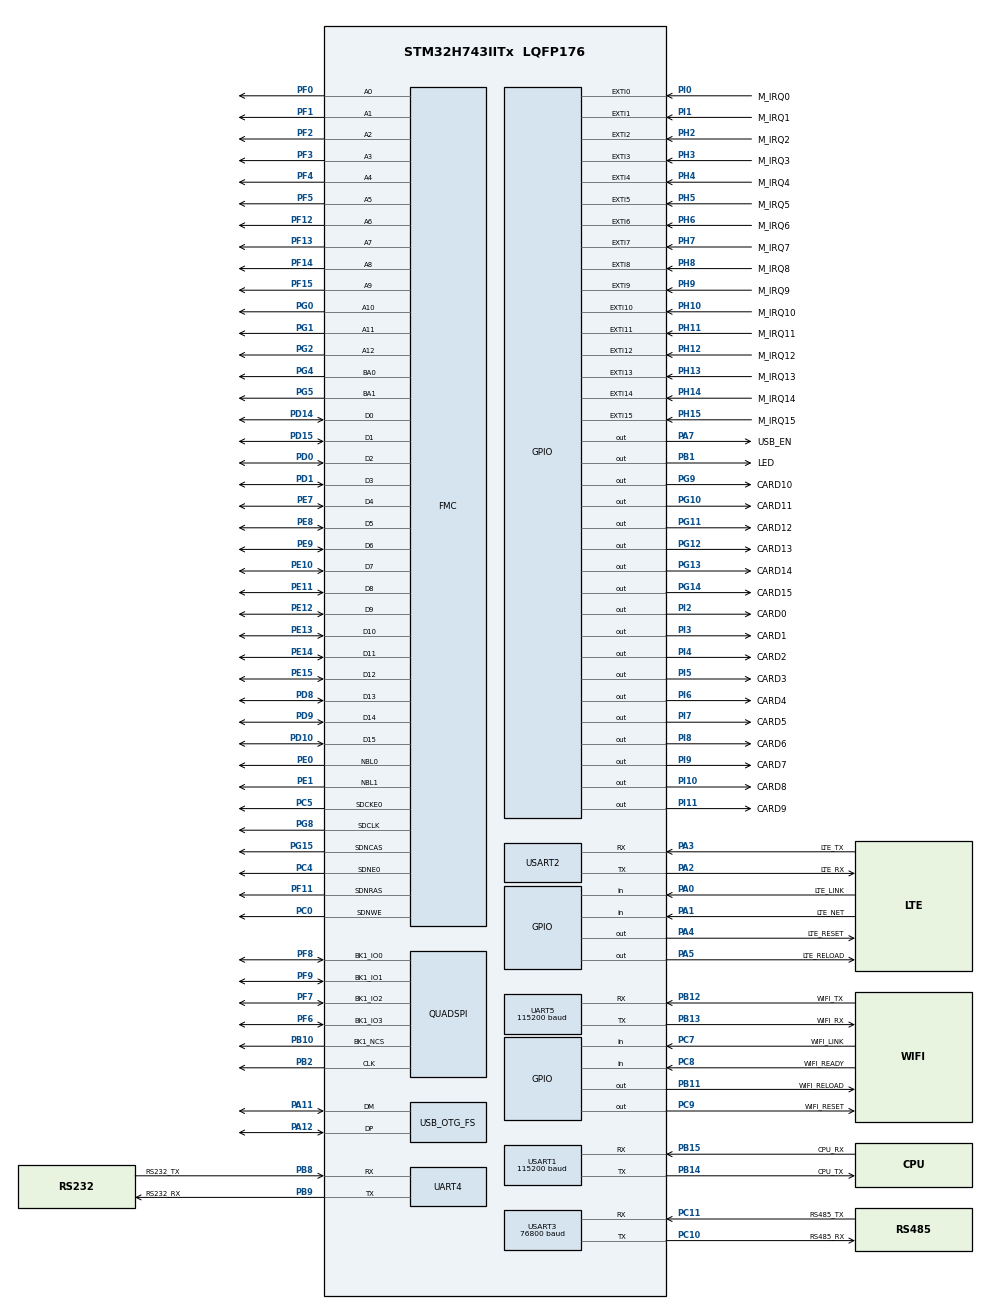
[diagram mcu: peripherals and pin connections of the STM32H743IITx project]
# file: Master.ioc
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CORTEX_M7.CPU_ICache=Enabled
Dma.Request0=USART3_RX
Dma.Request1=USART3_TX
Dma.Request2=UART5_RX
Dma.Request3=UART5_TX
Dma.Request4=USART1_RX
Dma.Request5=USART1_TX
Dma.Request6=USART2_RX
Dma.Request7=UART4_RX
Dma.Request8=UART4_TX
Dma.Request9=USART2_TX
Dma.UART4_RX.7.Direction=DMA_PERIPH_TO_MEMORY
Dma.UART4_RX.7.EventEnable=DISABLE
Dma.UART4_RX.7.FIFOMode=DMA_FIFOMODE_DISABLE
Dma.UART4_RX.7.Instance=DMA1_Stream1
Dma.UART4_RX.7.MemDataAlignment=DMA_MDATAALIGN_BYTE
Dma.UART4_RX.7.MemInc=DMA_MINC_ENABLE
Dma.UART4_RX.7.Mode=DMA_NORMAL
Dma.UART4_RX.7.PeriphDataAlignment=DMA_PDATAALIGN_BYTE
Dma.UART4_RX.7.PeriphInc=DMA_PINC_DISABLE
Dma.UART4_RX.7.Polarity=HAL_DMAMUX_REQ_GEN_RISING
Dma.UART4_RX.7.Priority=DMA_PRIORITY_LOW
Dma.UART4_RX.7.RequestNumber=1
Dma.UART4_RX.7.SignalID=NONE
Dma.UART4_RX.7.SyncEnable=DISABLE
Dma.UART4_RX.7.SyncPolarity=HAL_DMAMUX_SYNC_NO_EVENT
Dma.UART4_RX.7.SyncRequestNumber=1
Dma.UART4_RX.7.SyncSignalID=NONE
Dma.UART4_TX.8.Direction=DMA_MEMORY_TO_PERIPH
Dma.UART4_TX.8.EventEnable=DISABLE
Dma.UART4_TX.8.FIFOMode=DMA_FIFOMODE_DISABLE
Dma.UART4_TX.8.Instance=DMA1_Stream4
Dma.UART4_TX.8.MemDataAlignment=DMA_MDATAALIGN_BYTE
Dma.UART4_TX.8.MemInc=DMA_MINC_ENABLE
Dma.UART4_TX.8.Mode=DMA_NORMAL
Dma.UART4_TX.8.PeriphDataAlignment=DMA_PDATAALIGN_BYTE
Dma.UART4_TX.8.PeriphInc=DMA_PINC_DISABLE
Dma.UART4_TX.8.Polarity=HAL_DMAMUX_REQ_GEN_RISING
Dma.UART4_TX.8.Priority=DMA_PRIORITY_LOW
Dma.UART4_TX.8.RequestNumber=1
Dma.UART4_TX.8.SignalID=NONE
Dma.UART4_TX.8.SyncEnable=DISABLE
Dma.UART4_TX.8.SyncPolarity=HAL_DMAMUX_SYNC_NO_EVENT
Dma.UART4_TX.8.SyncRequestNumber=1
Dma.UART4_TX.8.SyncSignalID=NONE
Dma.UART5_RX.2.Direction=DMA_PERIPH_TO_MEMORY
Dma.UART5_RX.2.EventEnable=DISABLE
Dma.UART5_RX.2.FIFOMode=DMA_FIFOMODE_DISABLE
Dma.UART5_RX.2.Instance=DMA1_Stream6
Dma.UART5_RX.2.MemDataAlignment=DMA_MDATAALIGN_BYTE
Dma.UART5_RX.2.MemInc=DMA_MINC_ENABLE
Dma.UART5_RX.2.Mode=DMA_NORMAL
Dma.UART5_RX.2.PeriphDataAlignment=DMA_PDATAALIGN_BYTE
Dma.UART5_RX.2.PeriphInc=DMA_PINC_DISABLE
Dma.UART5_RX.2.Polarity=HAL_DMAMUX_REQ_GEN_RISING
Dma.UART5_RX.2.Priority=DMA_PRIORITY_MEDIUM
Dma.UART5_RX.2.RequestNumber=1
Dma.UART5_RX.2.SignalID=NONE
Dma.UART5_RX.2.SyncEnable=DISABLE
Dma.UART5_RX.2.SyncPolarity=HAL_DMAMUX_SYNC_NO_EVENT
Dma.UART5_RX.2.SyncRequestNumber=1
Dma.UART5_RX.2.SyncSignalID=NONE
Dma.UART5_TX.3.Direction=DMA_MEMORY_TO_PERIPH
Dma.UART5_TX.3.EventEnable=DISABLE
Dma.UART5_TX.3.FIFOMode=DMA_FIFOMODE_DISABLE
Dma.UART5_TX.3.Instance=DMA1_Stream7
Dma.UART5_TX.3.MemDataAlignment=DMA_MDATAALIGN_BYTE
Dma.UART5_TX.3.MemInc=DMA_MINC_ENABLE
Dma.UART5_TX.3.Mode=DMA_NORMAL
Dma.UART5_TX.3.PeriphDataAlignment=DMA_PDATAALIGN_BYTE
Dma.UART5_TX.3.PeriphInc=DMA_PINC_DISABLE
Dma.UART5_TX.3.Polarity=HAL_DMAMUX_REQ_GEN_RISING
Dma.UART5_TX.3.Priority=DMA_PRIORITY_LOW
Dma.UART5_TX.3.RequestNumber=1
Dma.UART5_TX.3.SignalID=NONE
Dma.UART5_TX.3.SyncEnable=DISABLE
Dma.UART5_TX.3.SyncPolarity=HAL_DMAMUX_SYNC_NO_EVENT
Dma.UART5_TX.3.SyncRequestNumber=1
Dma.UART5_TX.3.SyncSignalID=NONE
Dma.USART1_RX.4.Direction=DMA_PERIPH_TO_MEMORY
Dma.USART1_RX.4.EventEnable=DISABLE
Dma.USART1_RX.4.FIFOMode=DMA_FIFOMODE_DISABLE
Dma.USART1_RX.4.Instance=DMA2_Stream0
Dma.USART1_RX.4.MemDataAlignment=DMA_MDATAALIGN_BYTE
Dma.USART1_RX.4.MemInc=DMA_MINC_ENABLE
Dma.USART1_RX.4.Mode=DMA_NORMAL
Dma.USART1_RX.4.PeriphDataAlignment=DMA_PDATAALIGN_BYTE
Dma.USART1_RX.4.PeriphInc=DMA_PINC_DISABLE
Dma.USART1_RX.4.Polarity=HAL_DMAMUX_REQ_GEN_RISING
Dma.USART1_RX.4.Priority=DMA_PRIORITY_VERY_HIGH
Dma.USART1_RX.4.RequestNumber=1
Dma.USART1_RX.4.SignalID=NONE
Dma.USART1_RX.4.SyncEnable=DISABLE
Dma.USART1_RX.4.SyncPolarity=HAL_DMAMUX_SYNC_NO_EVENT
Dma.USART1_RX.4.SyncRequestNumber=1
Dma.USART1_RX.4.SyncSignalID=NONE
Dma.USART1_TX.5.Direction=DMA_MEMORY_TO_PERIPH
Dma.USART1_TX.5.EventEnable=DISABLE
Dma.USART1_TX.5.FIFOMode=DMA_FIFOMODE_DISABLE
Dma.USART1_TX.5.Instance=DMA2_Stream1
Dma.USART1_TX.5.MemDataAlignment=DMA_MDATAALIGN_BYTE
Dma.USART1_TX.5.MemInc=DMA_MINC_ENABLE
Dma.USART1_TX.5.Mode=DMA_NORMAL
Dma.USART1_TX.5.PeriphDataAlignment=DMA_PDATAALIGN_BYTE
Dma.USART1_TX.5.PeriphInc=DMA_PINC_DISABLE
Dma.USART1_TX.5.Polarity=HAL_DMAMUX_REQ_GEN_RISING
Dma.USART1_TX.5.Priority=DMA_PRIORITY_HIGH
Dma.USART1_TX.5.RequestNumber=1
Dma.USART1_TX.5.SignalID=NONE
Dma.USART1_TX.5.SyncEnable=DISABLE
Dma.USART1_TX.5.SyncPolarity=HAL_DMAMUX_SYNC_NO_EVENT
Dma.USART1_TX.5.SyncRequestNumber=1
Dma.USART1_TX.5.SyncSignalID=NONE
Dma.USART2_RX.6.Direction=DMA_PERIPH_TO_MEMORY
Dma.USART2_RX.6.EventEnable=DISABLE
Dma.USART2_RX.6.FIFOMode=DMA_FIFOMODE_DISABLE
Dma.USART2_RX.6.Instance=DMA1_Stream0
Dma.USART2_RX.6.MemDataAlignment=DMA_MDATAALIGN_BYTE
Dma.USART2_RX.6.MemInc=DMA_MINC_ENABLE
Dma.USART2_RX.6.Mode=DMA_NORMAL
Dma.USART2_RX.6.PeriphDataAlignment=DMA_PDATAALIGN_BYTE
Dma.USART2_RX.6.PeriphInc=DMA_PINC_DISABLE
Dma.USART2_RX.6.Polarity=HAL_DMAMUX_REQ_GEN_RISING
Dma.USART2_RX.6.Priority=DMA_PRIORITY_LOW
Dma.USART2_RX.6.RequestNumber=1
Dma.USART2_RX.6.SignalID=NONE
Dma.USART2_RX.6.SyncEnable=DISABLE
Dma.USART2_RX.6.SyncPolarity=HAL_DMAMUX_SYNC_NO_EVENT
Dma.USART2_RX.6.SyncRequestNumber=1
Dma.USART2_RX.6.SyncSignalID=NONE
Dma.USART2_TX.9.Direction=DMA_MEMORY_TO_PERIPH
Dma.USART2_TX.9.EventEnable=DISABLE
Dma.USART2_TX.9.FIFOMode=DMA_FIFOMODE_DISABLE
Dma.USART2_TX.9.Instance=DMA1_Stream5
Dma.USART2_TX.9.MemDataAlignment=DMA_MDATAALIGN_BYTE
Dma.USART2_TX.9.MemInc=DMA_MINC_ENABLE
Dma.USART2_TX.9.Mode=DMA_NORMAL
Dma.USART2_TX.9.PeriphDataAlignment=DMA_PDATAALIGN_BYTE
Dma.USART2_TX.9.PeriphInc=DMA_PINC_DISABLE
Dma.USART2_TX.9.Polarity=HAL_DMAMUX_REQ_GEN_RISING
Dma.USART2_TX.9.Priority=DMA_PRIORITY_LOW
Dma.USART2_TX.9.RequestNumber=1
Dma.USART2_TX.9.SignalID=NONE
Dma.USART2_TX.9.SyncEnable=DISABLE
Dma.USART2_TX.9.SyncPolarity=HAL_DMAMUX_SYNC_NO_EVENT
Dma.USART2_TX.9.SyncRequestNumber=1
Dma.USART2_TX.9.SyncSignalID=NONE
Dma.USART3_RX.0.Direction=DMA_PERIPH_TO_MEMORY
Dma.USART3_RX.0.EventEnable=DISABLE
Dma.USART3_RX.0.FIFOMode=DMA_FIFOMODE_DISABLE
Dma.USART3_RX.0.Instance=DMA1_Stream2
Dma.USART3_RX.0.MemDataAlignment=DMA_MDATAALIGN_BYTE
Dma.USART3_RX.0.MemInc=DMA_MINC_ENABLE
Dma.USART3_RX.0.Mode=DMA_NORMAL
Dma.USART3_RX.0.PeriphDataAlignment=DMA_PDATAALIGN_BYTE
Dma.USART3_RX.0.PeriphInc=DMA_PINC_DISABLE
Dma.USART3_RX.0.Polarity=HAL_DMAMUX_REQ_GEN_RISING
Dma.USART3_RX.0.Priority=DMA_PRIORITY_LOW
Dma.USART3_RX.0.RequestNumber=1
Dma.USART3_RX.0.SignalID=NONE
Dma.USART3_RX.0.SyncEnable=DISABLE
Dma.USART3_RX.0.SyncPolarity=HAL_DMAMUX_SYNC_NO_EVENT
Dma.USART3_RX.0.SyncRequestNumber=1
Dma.USART3_RX.0.SyncSignalID=NONE
Dma.USART3_TX.1.Direction=DMA_MEMORY_TO_PERIPH
Dma.USART3_TX.1.EventEnable=DISABLE
Dma.USART3_TX.1.FIFOMode=DMA_FIFOMODE_DISABLE
Dma.USART3_TX.1.Instance=DMA1_Stream3
Dma.USART3_TX.1.MemDataAlignment=DMA_MDATAALIGN_BYTE
Dma.USART3_TX.1.MemInc=DMA_MINC_ENABLE
Dma.USART3_TX.1.Mode=DMA_NORMAL
Dma.USART3_TX.1.PeriphDataAlignment=DMA_PDATAALIGN_BYTE
Dma.USART3_TX.1.PeriphInc=DMA_PINC_DISABLE
Dma.USART3_TX.1.Polarity=HAL_DMAMUX_REQ_GEN_RISING
Dma.USART3_TX.1.Priority=DMA_PRIORITY_LOW
Dma.USART3_TX.1.RequestNumber=1
Dma.USART3_TX.1.SignalID=NONE
Dma.USART3_TX.1.SyncEnable=DISABLE
Dma.USART3_TX.1.SyncPolarity=HAL_DMAMUX_SYNC_NO_EVENT
Dma.USART3_TX.1.SyncRequestNumber=1
Dma.USART3_TX.1.SyncSignalID=NONE
FMC.CASLatency1=FMC_SDRAM_CAS_LATENCY_3
FMC.ColumnBitsNumber1=FMC_SDRAM_COLUMN_BITS_NUM_9
FMC.ExitSelfRefreshDelay1=9
FMC.LoadToActiveDelay1=2
FMC.RCDDelay1=2
FMC.RPDelay1=2
FMC.ReadBurst1=FMC_SDRAM_RBURST_ENABLE
FMC.ReadPipeDelay1=FMC_SDRAM_RPIPE_DELAY_0
FMC.RowCycleDelay1=8
FMC.SDClockPeriod1=FMC_SDRAM_CLOCK_PERIOD_2
FMC.SelfRefreshTime1=6
FMC.WriteRecoveryTime1=4
FREERTOS.BinarySemaphores01=Recive_Cpu,Dynamic,NULL;Recive_Rs485,Dynamic,NULL;Recive_Rs232,Dynamic,NULL;Recive_Wifi,Dynamic,NULL;Recive_Lte,Dynamic,NULL;Code_Signal,Dynamic,NULL;Recive_Usb,Dynamic,NULL
FREERTOS.Mutexes01=shellMutex,Dynamic,NULL
FREERTOS.Queues01=CodeQueue,16,uint16_t,0,Dynamic,NULL,NULL;UserQueue,4,Save_User,0,Dynamic,NULL,NULL;SureQueue,16,IRQ_Request,0,Dynamic,NULL,NULL
FREERTOS.Tasks01=Shell,-2,256,Shell_Task,Default,&shell,Dynamic,NULL,NULL;Screen,-1,256,Screen_Task,Default,Dwin_Object,Dynamic,NULL,NULL;RS485,-2,128,RS485_Task,Default,Slave2_Object,Dynamic,NULL,NULL;Wifi,-2,256,Wifi_Task,Default,Slave1_Object,Dynamic,NULL,NULL;C4G,-2,256,C4G_Task,Default,Slave1_Object,Dynamic,NULL,NULL;Master,2,256,Master_Task,Default,Slave1_Object,Dynamic,NULL,NULL;Interrupt,3,256,IRQ_Task,Default,NULL,Dynamic,NULL,NULL;control,0,512,Control_Task,Default,NULL,Dynamic,NULL,NULL;Transimt,2,512,Transimt_Task,Default,NULL,Dynamic,NULL,NULL;Treport,-3,512,Report_Task,Default,NULL,Dynamic,NULL,NULL
FREERTOS.Timers01=Report,Report_Callback,osTimerPeriodic,Default,&IRQ_Table,Dynamic,NULL;Modbus,Modbus_Callback,osTimerPeriodic,Default,NULL,Dynamic,NULL
FREERTOS.configCHECK_FOR_STACK_OVERFLOW=2
FREERTOS.configTIMER_TASK_PRIORITY=3
FREERTOS.configTOTAL_HEAP_SIZE=262144
FREERTOS.configUSE_COUNTING_SEMAPHORES=1
FREERTOS.configUSE_MALLOC_FAILED_HOOK=1
FREERTOS.configUSE_TIMERS=1
Mcu.Family=STM32H7
Mcu.Name=STM32H743IITx
Mcu.Package=LQFP176
NVIC.DMA1_Stream0_IRQn=true\:5\:0\:true\:false\:true\:true\:false\:true\:true
NVIC.DMA1_Stream1_IRQn=true\:5\:0\:true\:false\:true\:true\:false\:true\:true
NVIC.DMA1_Stream2_IRQn=true\:5\:0\:true\:false\:true\:true\:false\:true\:true
NVIC.DMA1_Stream3_IRQn=true\:5\:0\:true\:false\:true\:true\:false\:true\:true
NVIC.DMA1_Stream4_IRQn=true\:5\:0\:true\:false\:true\:true\:false\:true\:true
NVIC.DMA1_Stream5_IRQn=true\:5\:0\:true\:false\:true\:true\:false\:true\:true
NVIC.DMA1_Stream6_IRQn=true\:5\:0\:true\:false\:true\:true\:false\:true\:true
NVIC.DMA1_Stream7_IRQn=true\:5\:0\:false\:false\:true\:true\:false\:true\:true
NVIC.DMA2_Stream0_IRQn=true\:5\:0\:true\:false\:true\:true\:false\:true\:true
NVIC.DMA2_Stream1_IRQn=true\:5\:0\:true\:false\:true\:true\:false\:true\:true
NVIC.EXTI0_IRQn=true\:5\:0\:true\:false\:true\:true\:true\:true\:true
NVIC.EXTI15_10_IRQn=true\:5\:0\:true\:false\:true\:true\:true\:true\:true
NVIC.EXTI1_IRQn=true\:5\:0\:true\:false\:true\:true\:true\:true\:true
NVIC.EXTI2_IRQn=true\:5\:0\:true\:false\:true\:true\:true\:true\:true
NVIC.EXTI3_IRQn=true\:5\:0\:true\:false\:true\:true\:true\:true\:true
NVIC.EXTI4_IRQn=true\:5\:0\:true\:false\:true\:true\:true\:true\:true
NVIC.EXTI9_5_IRQn=true\:5\:0\:true\:false\:true\:true\:true\:true\:true
NVIC.FLASH_IRQn=true\:5\:0\:false\:false\:true\:false\:true\:true\:true
NVIC.OTG_FS_IRQn=true\:5\:0\:false\:false\:true\:true\:false\:true\:true
NVIC.PriorityGroup=NVIC_PRIORITYGROUP_4
NVIC.TIM17_IRQn=true\:1\:0\:true\:false\:true\:false\:false\:true\:true
NVIC.TimeBase=TIM17_IRQn
NVIC.TimeBaseIP=TIM17
NVIC.UART4_IRQn=true\:5\:0\:true\:false\:true\:true\:true\:true\:true
NVIC.UART5_IRQn=true\:5\:0\:true\:false\:true\:true\:true\:true\:true
NVIC.USART1_IRQn=true\:5\:0\:true\:false\:true\:true\:true\:true\:true
NVIC.USART2_IRQn=true\:5\:0\:true\:false\:true\:true\:true\:true\:true
NVIC.USART3_IRQn=true\:5\:0\:true\:false\:true\:true\:true\:true\:true
PA0.GPIO_Label=LTE_LINK
PA0.GPIO_PuPd=GPIO_PULLUP
PA0.Signal=GPIO_Input
PA1.GPIO_Label=LTE_NET
PA1.GPIO_PuPd=GPIO_PULLUP
PA1.Signal=GPIO_Input
PA11.GPIO_PuPd=GPIO_PULLUP
PA11.GPIO_Speed=GPIO_SPEED_FREQ_VERY_HIGH
PA11.Mode=Device_Only
PA11.Signal=USB_OTG_FS_DM
PA12.GPIO_PuPd=GPIO_PULLUP
PA12.GPIO_Speed=GPIO_SPEED_FREQ_VERY_HIGH
PA12.Mode=Device_Only
PA12.Signal=USB_OTG_FS_DP
PA13\ (JTMS/SWDIO).Mode=JTAG_5_pins
PA13\ (JTMS/SWDIO).Signal=DEBUG_JTMS-SWDIO
PA14\ (JTCK/SWCLK).Mode=JTAG_5_pins
PA14\ (JTCK/SWCLK).Signal=DEBUG_JTCK-SWCLK
PA15\ (JTDI).Mode=JTAG_5_pins
PA15\ (JTDI).Signal=DEBUG_JTDI
PA2.GPIO_Label=LTE_RX
PA2.GPIO_PuPd=GPIO_PULLUP
PA2.GPIO_Speed=GPIO_SPEED_FREQ_HIGH
PA2.Mode=Asynchronous
PA2.Signal=USART2_TX
PA3.GPIO_Label=LTE_TX
PA3.GPIO_Speed=GPIO_SPEED_FREQ_HIGH
PA3.Mode=Asynchronous
PA3.Signal=USART2_RX
PA4.GPIO_Label=LTE_RESET
PA4.GPIO_PuPd=GPIO_PULLUP
PA4.PinState=GPIO_PIN_SET
PA4.Signal=GPIO_Output
PA5.GPIO_Label=LTE_RELOAD
PA5.GPIO_PuPd=GPIO_PULLUP
PA5.PinState=GPIO_PIN_SET
PA5.Signal=GPIO_Output
PA7.GPIO_Label=USB_EN
PA7.GPIO_PuPd=GPIO_PULLUP
PA7.Signal=GPIO_Output
PB1.GPIO_Label=LED
PB1.GPIO_PuPd=GPIO_PULLUP
PB1.PinState=GPIO_PIN_SET
PB1.Signal=GPIO_Output
PB10.Mode=Single Bank 1
PB10.Signal=QUADSPI_BK1_NCS
PB11.GPIO_Label=WIFI_RELOAD
PB11.GPIO_PuPd=GPIO_PULLUP
PB11.PinState=GPIO_PIN_SET
PB11.Signal=GPIO_Output
PB12.GPIO_Label=WIFI_TX
PB12.GPIO_PuPd=GPIO_NOPULL
PB12.Mode=Asynchronous
PB12.Signal=UART5_RX
PB13.GPIO_Label=WIFI_RX
PB13.Mode=Asynchronous
PB13.Signal=UART5_TX
PB14.GPIO_Label=CPU_TX
PB14.GPIO_PuPd=GPIO_PULLUP
PB14.GPIO_Speed=GPIO_SPEED_FREQ_VERY_HIGH
PB14.Mode=Asynchronous
PB14.Signal=USART1_TX
PB15.GPIO_Label=CPU_RX
PB15.GPIO_PuPd=GPIO_PULLUP
PB15.GPIO_Speed=GPIO_SPEED_FREQ_VERY_HIGH
PB15.Mode=Asynchronous
PB15.Signal=USART1_RX
PB2.Mode=Single Bank 1
PB2.Signal=QUADSPI_CLK
PB3\ (JTDO/TRACESWO).Mode=JTAG_5_pins
PB3\ (JTDO/TRACESWO).PinAttribute=Free
PB3\ (JTDO/TRACESWO).Signal=DEBUG_JTDO-SWO
PB4\ (NJTRST).Mode=JTAG_5_pins
PB4\ (NJTRST).PinAttribute=Free
PB4\ (NJTRST).Signal=DEBUG_JTRST
PB8.GPIO_Label=RS232_TX
PB8.GPIO_PuPd=GPIO_PULLUP
PB8.GPIO_Speed=GPIO_SPEED_FREQ_MEDIUM
PB8.Mode=Asynchronous
PB8.PinAttribute=Free
PB8.Signal=UART4_RX
PB9.GPIO_Label=RS232_RX
PB9.GPIO_PuPd=GPIO_PULLUP
PB9.GPIO_Speed=GPIO_SPEED_FREQ_MEDIUM
PB9.Mode=Asynchronous
PB9.PinAttribute=Free
PB9.Signal=UART4_TX
PC0.Signal=FMC_SDNWE
PC10.GPIO_Label=RS485_RX
PC10.GPIO_PuPd=GPIO_PULLUP
PC10.GPIO_Speed=GPIO_SPEED_FREQ_LOW
PC10.Mode=Asynchronous
PC10.Signal=USART3_TX
PC11.GPIO_Label=RS485_TX
PC11.GPIO_PuPd=GPIO_PULLUP
PC11.Mode=Asynchronous
PC11.Signal=USART3_RX
PC14-OSC32_IN\ (OSC32_IN).Mode=LSE-External-Oscillator
PC14-OSC32_IN\ (OSC32_IN).Signal=RCC_OSC32_IN
PC15-OSC32_OUT\ (OSC32_OUT).Mode=LSE-External-Oscillator
PC15-OSC32_OUT\ (OSC32_OUT).Signal=RCC_OSC32_OUT
PC4.Mode=SdramChipSelect1_1
PC4.Signal=FMC_SDNE0
PC5.Mode=SdramChipSelect1_1
PC5.Signal=FMC_SDCKE0
PC7.GPIO_Label=WIFI_LINK
PC7.GPIO_PuPd=GPIO_PULLUP
PC7.Signal=GPIO_Input
PC8.GPIO_Label=WIFI_READY
PC8.GPIO_PuPd=GPIO_PULLUP
PC8.Signal=GPIO_Input
PC9.GPIO_Label=WIFI_RESET
PC9.GPIO_PuPd=GPIO_PULLUP
PC9.PinState=GPIO_PIN_SET
PC9.Signal=GPIO_Output
PD0.Signal=FMC_D2_DA2
PD1.Signal=FMC_D3_DA3
PD10.Signal=FMC_D15_DA15
PD14.Signal=FMC_D0_DA0
PD15.Signal=FMC_D1_DA1
PD8.Signal=FMC_D13_DA13
PD9.Signal=FMC_D14_DA14
PE0.PinAttribute=Free
PE0.Signal=FMC_NBL0
PE1.PinAttribute=Free
PE1.Signal=FMC_NBL1
PE10.Signal=FMC_D7_DA7
PE11.Signal=FMC_D8_DA8
PE12.Signal=FMC_D9_DA9
PE13.Signal=FMC_D10_DA10
PE14.Signal=FMC_D11_DA11
PE15.Signal=FMC_D12_DA12
PE7.Signal=FMC_D4_DA4
PE8.Signal=FMC_D5_DA5
PE9.Signal=FMC_D6_DA6
PF0.Signal=FMC_A0
PF1.Signal=FMC_A1
PF11.Signal=FMC_SDNRAS
PF12.Signal=FMC_A6
PF13.Signal=FMC_A7
PF14.Signal=FMC_A8
PF15.Signal=FMC_A9
PF2.Signal=FMC_A2
PF3.Signal=FMC_A3
PF4.Signal=FMC_A4
PF5.Signal=FMC_A5
PF6.Mode=Single Bank 1
PF6.Signal=QUADSPI_BK1_IO3
PF7.Mode=Single Bank 1
PF7.Signal=QUADSPI_BK1_IO2
PF8.Mode=Single Bank 1
PF8.Signal=QUADSPI_BK1_IO0
PF9.Mode=Single Bank 1
PF9.Signal=QUADSPI_BK1_IO1
PG0.Signal=FMC_A10
PG1.Signal=FMC_A11
PG10.GPIO_Label=CARD11
PG10.GPIO_PuPd=GPIO_PULLUP
PG10.PinState=GPIO_PIN_SET
PG10.Signal=GPIO_Output
PG11.GPIO_Label=CARD12
PG11.GPIO_PuPd=GPIO_PULLUP
PG11.PinState=GPIO_PIN_SET
PG11.Signal=GPIO_Output
PG12.GPIO_Label=CARD13
PG12.GPIO_PuPd=GPIO_PULLUP
PG12.PinState=GPIO_PIN_SET
PG12.Signal=GPIO_Output
PG13.GPIO_Label=CARD14
PG13.GPIO_PuPd=GPIO_PULLUP
PG13.PinState=GPIO_PIN_SET
PG13.Signal=GPIO_Output
PG14.GPIO_Label=CARD15
PG14.GPIO_PuPd=GPIO_PULLUP
PG14.PinAttribute=Free
PG14.PinState=GPIO_PIN_SET
PG14.Signal=GPIO_Output
PG15.PinAttribute=Free
PG15.Signal=FMC_SDNCAS
PG2.Signal=FMC_A12
PG4.Signal=FMC_A14_BA0
PG5.Signal=FMC_A15_BA1
PG8.Signal=FMC_SDCLK
PG9.GPIO_Label=CARD10
PG9.GPIO_PuPd=GPIO_PULLUP
PG9.PinState=GPIO_PIN_SET
PG9.Signal=GPIO_Output
PH0-OSC_IN\ (PH0).Mode=HSE-External-Oscillator
PH0-OSC_IN\ (PH0).Signal=RCC_OSC_IN
PH1-OSC_OUT\ (PH1).Mode=HSE-External-Oscillator
PH1-OSC_OUT\ (PH1).Signal=RCC_OSC_OUT
PH10.GPIO_Label=M_IRQ10
PH10.GPIO_ModeDefaultEXTI=GPIO_MODE_IT_FALLING
PH10.GPIO_PuPd=GPIO_PULLUP
PH10.Signal=GPXTI10
PH11.GPIO_Label=M_IRQ11
PH11.GPIO_ModeDefaultEXTI=GPIO_MODE_IT_FALLING
PH11.GPIO_PuPd=GPIO_PULLUP
PH11.Signal=GPXTI11
PH12.GPIO_Label=M_IRQ12
PH12.GPIO_ModeDefaultEXTI=GPIO_MODE_IT_FALLING
PH12.GPIO_PuPd=GPIO_PULLUP
PH12.Signal=GPXTI12
PH13.GPIO_Label=M_IRQ13
PH13.GPIO_ModeDefaultEXTI=GPIO_MODE_IT_FALLING
PH13.GPIO_PuPd=GPIO_PULLUP
PH13.Signal=GPXTI13
PH14.GPIO_Label=M_IRQ14
PH14.GPIO_ModeDefaultEXTI=GPIO_MODE_IT_FALLING
PH14.GPIO_PuPd=GPIO_PULLUP
PH14.Signal=GPXTI14
PH15.GPIO_Label=M_IRQ15
PH15.GPIO_ModeDefaultEXTI=GPIO_MODE_IT_FALLING
PH15.GPIO_PuPd=GPIO_PULLUP
PH15.Signal=GPXTI15
PH2.GPIO_Label=M_IRQ2
PH2.GPIO_ModeDefaultEXTI=GPIO_MODE_IT_FALLING
PH2.GPIO_PuPd=GPIO_PULLUP
PH2.Signal=GPXTI2
PH3.GPIO_Label=M_IRQ3
PH3.GPIO_ModeDefaultEXTI=GPIO_MODE_IT_FALLING
PH3.GPIO_PuPd=GPIO_PULLUP
PH3.Signal=GPXTI3
PH4.GPIO_Label=M_IRQ4
PH4.GPIO_ModeDefaultEXTI=GPIO_MODE_IT_FALLING
PH4.GPIO_PuPd=GPIO_PULLUP
PH4.Signal=GPXTI4
PH5.GPIO_Label=M_IRQ5
PH5.GPIO_ModeDefaultEXTI=GPIO_MODE_IT_FALLING
PH5.GPIO_PuPd=GPIO_PULLUP
PH5.Signal=GPXTI5
PH6.GPIO_Label=M_IRQ6
PH6.GPIO_ModeDefaultEXTI=GPIO_MODE_IT_FALLING
PH6.GPIO_PuPd=GPIO_PULLUP
PH6.Signal=GPXTI6
PH7.GPIO_Label=M_IRQ7
PH7.GPIO_ModeDefaultEXTI=GPIO_MODE_IT_FALLING
PH7.GPIO_PuPd=GPIO_PULLUP
PH7.Signal=GPXTI7
PH8.GPIO_Label=M_IRQ8
PH8.GPIO_ModeDefaultEXTI=GPIO_MODE_IT_FALLING
PH8.GPIO_PuPd=GPIO_PULLUP
PH8.Signal=GPXTI8
PH9.GPIO_Label=M_IRQ9
PH9.GPIO_ModeDefaultEXTI=GPIO_MODE_IT_FALLING
PH9.GPIO_PuPd=GPIO_PULLUP
PH9.Signal=GPXTI9
PI0.GPIO_Label=M_IRQ0
PI0.GPIO_ModeDefaultEXTI=GPIO_MODE_IT_FALLING
PI0.GPIO_PuPd=GPIO_PULLUP
PI0.Signal=GPXTI0
PI1.GPIO_Label=M_IRQ1
PI1.GPIO_ModeDefaultEXTI=GPIO_MODE_IT_FALLING
PI1.GPIO_PuPd=GPIO_PULLUP
PI1.Signal=GPXTI1
PI10.GPIO_Label=CARD8
PI10.GPIO_PuPd=GPIO_PULLUP
PI10.PinState=GPIO_PIN_SET
PI10.Signal=GPIO_Output
PI11.GPIO_Label=CARD9
PI11.GPIO_PuPd=GPIO_PULLUP
PI11.PinState=GPIO_PIN_SET
PI11.Signal=GPIO_Output
PI2.GPIO_Label=CARD0
PI2.GPIO_PuPd=GPIO_PULLUP
PI2.PinState=GPIO_PIN_SET
PI2.Signal=GPIO_Output
PI3.GPIO_Label=CARD1
PI3.GPIO_PuPd=GPIO_PULLUP
PI3.PinState=GPIO_PIN_SET
PI3.Signal=GPIO_Output
PI4.GPIO_Label=CARD2
PI4.GPIO_PuPd=GPIO_PULLUP
PI4.PinAttribute=Free
PI4.PinState=GPIO_PIN_SET
PI4.Signal=GPIO_Output
PI5.GPIO_Label=CARD3
PI5.GPIO_PuPd=GPIO_PULLUP
PI5.PinAttribute=Free
PI5.PinState=GPIO_PIN_SET
PI5.Signal=GPIO_Output
PI6.GPIO_Label=CARD4
PI6.GPIO_PuPd=GPIO_PULLUP
PI6.PinAttribute=Free
PI6.PinState=GPIO_PIN_SET
PI6.Signal=GPIO_Output
PI7.GPIO_Label=CARD5
PI7.GPIO_PuPd=GPIO_PULLUP
PI7.PinAttribute=Free
PI7.PinState=GPIO_PIN_SET
PI7.Signal=GPIO_Output
PI8.GPIO_Label=CARD6
PI8.GPIO_PuPd=GPIO_PULLUP
PI8.PinState=GPIO_PIN_SET
PI8.Signal=GPIO_Output
PI9.GPIO_Label=CARD7
PI9.GPIO_PuPd=GPIO_PULLUP
PI9.PinState=GPIO_PIN_SET
PI9.Signal=GPIO_Output
ProjectManager.HeapSize=0x200
ProjectManager.StackSize=0x800
ProjectManager.TargetToolchain=MDK-ARM V5.27
RCC.ADCFreq_Value=50390625
RCC.APB1Freq_Value=120000000
RCC.APB2Freq_Value=120000000
RCC.APB3Freq_Value=120000000
RCC.APB4Freq_Value=120000000
RCC.CortexFreq_Value=480000000
RCC.D1PPRE=RCC_APB3_DIV2
RCC.D2PPRE1=RCC_APB1_DIV2
RCC.D2PPRE2=RCC_APB2_DIV2
RCC.D3PPRE=RCC_APB4_DIV2
RCC.DIVM1=10
RCC.DIVN1=384
RCC.DIVQ1=10
RCC.HCLKFreq_Value=240000000
RCC.HPRE=RCC_HCLK_DIV2
RCC.HSE_VALUE=25000000
RCC.PLL1_VCI_Range-AdvancedSettings=RCC_PLL1VCIRANGE_0
RCC.PLL2FRACN=0
RCC.PLL2_VCI_Range-AdvancedSettings=RCC_PLL2VCIRANGE_0
RCC.PLL2_VCO_SEL-AdvancedSettings=RCC_PLL2VCOMEDIUM
RCC.PLL3FRACN=0
RCC.PLLFRACN=0
RCC.PLLSourceVirtual=RCC_PLLSOURCE_HSE
RCC.SYSCLKFreq_VALUE=480000000
RCC.SYSCLKSource=RCC_SYSCLKSOURCE_PLLCLK
RCC.USBCLockSelection=RCC_USBCLKSOURCE_HSI48
RCC.USBFreq_Value=48000000
SH.FMC_A0.0=FMC_A0,13b-sda1
SH.FMC_A1.0=FMC_A1,13b-sda1
SH.FMC_A10.0=FMC_A10,13b-sda1
SH.FMC_A11.0=FMC_A11,13b-sda1
SH.FMC_A12.0=FMC_A12,13b-sda1
SH.FMC_A14_BA0.0=FMC_A14
SH.FMC_A14_BA0.1=FMC_BA0,FourSdramBanks1
SH.FMC_A15_BA1.0=FMC_BA1,FourSdramBanks1
SH.FMC_A2.0=FMC_A2,13b-sda1
SH.FMC_A3.0=FMC_A3,13b-sda1
SH.FMC_A4.0=FMC_A4,13b-sda1
SH.FMC_A5.0=FMC_A5,13b-sda1
SH.FMC_A6.0=FMC_A6,13b-sda1
SH.FMC_A7.0=FMC_A7,13b-sda1
SH.FMC_A8.0=FMC_A8,13b-sda1
SH.FMC_A9.0=FMC_A9,13b-sda1
SH.FMC_D0_DA0.0=FMC_D0,sd-16b-d1
SH.FMC_D10_DA10.0=FMC_D10,sd-16b-d1
SH.FMC_D11_DA11.0=FMC_D11,sd-16b-d1
SH.FMC_D12_DA12.0=FMC_D12,sd-16b-d1
SH.FMC_D13_DA13.0=FMC_D13,sd-16b-d1
SH.FMC_D14_DA14.0=FMC_D14,sd-16b-d1
SH.FMC_D15_DA15.0=FMC_D15,sd-16b-d1
SH.FMC_D1_DA1.0=FMC_D1,sd-16b-d1
SH.FMC_D2_DA2.0=FMC_D2,sd-16b-d1
SH.FMC_D3_DA3.0=FMC_D3,sd-16b-d1
SH.FMC_D4_DA4.0=FMC_D4,sd-16b-d1
SH.FMC_D5_DA5.0=FMC_D5,sd-16b-d1
SH.FMC_D6_DA6.0=FMC_D6,sd-16b-d1
SH.FMC_D7_DA7.0=FMC_D7,sd-16b-d1
SH.FMC_D8_DA8.0=FMC_D8,sd-16b-d1
SH.FMC_D9_DA9.0=FMC_D9,sd-16b-d1
SH.FMC_NBL0.0=FMC_NBL0,Sd2ByteEnable1
SH.FMC_NBL1.0=FMC_NBL1,Sd2ByteEnable1
SH.FMC_SDCLK.0=FMC_SDCLK,13b-sda1
SH.FMC_SDNCAS.0=FMC_SDNCAS,13b-sda1
SH.FMC_SDNRAS.0=FMC_SDNRAS,13b-sda1
SH.FMC_SDNWE.0=FMC_SDNWE,13b-sda1
UART5.BaudRate=115200
USART1.BaudRate=115200
USART1.OverSampling=UART_OVERSAMPLING_8
USART1.SwapParam=ADVFEATURE_SWAP_DISABLE
USART1.VirtualMode-Asynchronous=VM_ASYNC
USART2.VirtualMode-Asynchronous=VM_ASYNC
USART3.BaudRate=76800
USART3.VirtualMode-Asynchronous=VM_ASYNC
USB_DEVICE.APP_RX_DATA_SIZE-CDC_FS=1024
USB_DEVICE.APP_TX_DATA_SIZE-CDC_FS=512
USB_DEVICE.CLASS_NAME_FS=CDC
USB_DEVICE.USBD_DEBUG_LEVEL-CDC_FS=0
USB_DEVICE.VirtualMode-CDC_FS=Cdc
USB_DEVICE.VirtualModeFS=Cdc_FS
USB_OTG_FS.VirtualMode=Device_Only
VP_FREERTOS_VS_CMSIS_V1.Mode=CMSIS_V1
VP_SYS_VS_tim17.Mode=TIM17
VP_USB_DEVICE_VS_USB_DEVICE_CDC_FS.Mode=CDC_FS
board=custom

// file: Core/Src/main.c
/* USER CODE BEGIN Header */
/**
 ******************************************************************************
 * @file           : main.c
 * @brief          : Main program body
 ******************************************************************************
 * @attention
 *
 * <h2><center>&copy; Copyright (c) 2022 STMicroelectronics.
 * All rights reserved.</center></h2>
 *
 * This software component is licensed by ST under BSD 3-Clause license,
 * the "License"; You may not use this file except in compliance with the
 * License. You may obtain a copy of the License at:
 *                        opensource.org/licenses/BSD-3-Clause
 *
 ******************************************************************************
 */
/* USER CODE END Header */
#include "main.h"
#include "cmsis_os.h"
#include "dma.h"
#include "quadspi.h"
#include "usart.h"
#include "usb_device.h"
#include "gpio.h"
#include "fmc.h"

/* USER CODE BEGIN Includes */
#include "shell_port.h"
// #include "dwin.h"
// #include "mdrtuslave.h"
/* USER CODE END Includes */

void SystemClock_Config(void);
void MX_FREERTOS_Init(void);

int main(void)
{

  /* Enable I-Cache---------------------------------------------------------*/
  SCB_EnableICache();

  /* MCU Configuration--------------------------------------------------------*/

  /* Reset of all peripherals, Initializes the Flash interface and the Systick. */
  HAL_Init();

  /* Configure the system clock */
  SystemClock_Config();

  /* USER CODE BEGIN SysInit */
  /*Open interrupt*/
  //  __set_FAULTMASK(0);
  //  __enable_irq();
  /*Solve the problem of abnormal operation of some peripherals
  caused by incomplete reset after power on.*/
  //  HAL_Delay(1000);
  /* USER CODE END SysInit */

  /* Initialize all configured peripherals */
  MX_GPIO_Init();
  MX_DMA_Init();
  MX_UART4_Init();
  MX_USART3_UART_Init();
  MX_UART5_Init();
  MX_USART1_UART_Init();
  MX_QUADSPI_Init();
  MX_USART2_UART_Init();
  MX_FMC_Init();
  /* USER CODE BEGIN 2 */
  /*Clear UIF flag bit of Hal library timer*/
  // TIM17->SR &= 0xFFFE;
  // extern TIM_HandleTypeDef htim17;
  // __HAL_TIM_ENABLE_IT(&htim17, TIM_FLAG_UPDATE);
  // if (__HAL_TIM_GET_FLAG(&htim17, TIM_FLAG_UPDATE))
  // {
  //   __HAL_TIM_CLEAR_FLAG(&htim17, TIM_FLAG_UPDATE);
  // }
  // HAL_Delay(2000);
  /* USER CODE END 2 */

  /* Call init function for freertos objects (in freertos.c) */
  MX_FREERTOS_Init();

  /* Start scheduler */
  osKernelStart();

  /* We should never get here as control is now taken by the scheduler */
  /* Infinite loop */
  while (1)
  {

    /* USER CODE BEGIN 3 */
#if defined(USING_DEBUG)
    // shellPrint(Shell_Object, "\x55\r\n");
    uint8_t data = 0x55;
    HAL_UART_Transmit(&huart3, &data, 1, 1000);
    HAL_Delay(1000);
#endif
  }
  /* USER CODE END 3 */
}

void SystemClock_Config(void)
{
  RCC_OscInitTypeDef RCC_OscInitStruct = {0};
  RCC_ClkInitTypeDef RCC_ClkInitStruct = {0};

  /** Supply configuration update enable
   */
  HAL_PWREx_ConfigSupply(PWR_LDO_SUPPLY);

  /** Configure the main internal regulator output voltage
   */
  __HAL_PWR_VOLTAGESCALING_CONFIG(PWR_REGULATOR_VOLTAGE_SCALE0);

  while (!__HAL_PWR_GET_FLAG(PWR_FLAG_VOSRDY))
  {
  }

  /** Initializes the RCC Oscillators according to the specified parameters
   * in the RCC_OscInitTypeDef structure.
   */
  RCC_OscInitStruct.OscillatorType = RCC_OSCILLATORTYPE_HSI48 | RCC_OSCILLATORTYPE_HSE;
  RCC_OscInitStruct.HSEState = RCC_HSE_ON;
  RCC_OscInitStruct.HSI48State = RCC_HSI48_ON;
  RCC_OscInitStruct.PLL.PLLState = RCC_PLL_ON;
  RCC_OscInitStruct.PLL.PLLSource = RCC_PLLSOURCE_HSE;
  RCC_OscInitStruct.PLL.PLLM = 10;
  RCC_OscInitStruct.PLL.PLLN = 384;
  RCC_OscInitStruct.PLL.PLLP = 2;
  RCC_OscInitStruct.PLL.PLLQ = 10;
  RCC_OscInitStruct.PLL.PLLR = 2;
  RCC_OscInitStruct.PLL.PLLRGE = RCC_PLL1VCIRANGE_1;
  RCC_OscInitStruct.PLL.PLLVCOSEL = RCC_PLL1VCOWIDE;
  RCC_OscInitStruct.PLL.PLLFRACN = 0;
  if (HAL_RCC_OscConfig(&RCC_OscInitStruct) != HAL_OK)
  {
    Error_Handler();
  }

  /** Initializes the CPU, AHB and APB buses clocks
   */
  RCC_ClkInitStruct.ClockType = RCC_CLOCKTYPE_HCLK | RCC_CLOCKTYPE_SYSCLK | RCC_CLOCKTYPE_PCLK1 | RCC_CLOCKTYPE_PCLK2 | RCC_CLOCKTYPE_D3PCLK1 | RCC_CLOCKTYPE_D1PCLK1;
  RCC_ClkInitStruct.SYSCLKSource = RCC_SYSCLKSOURCE_PLLCLK;
  RCC_ClkInitStruct.SYSCLKDivider = RCC_SYSCLK_DIV1;
  RCC_ClkInitStruct.AHBCLKDivider = RCC_HCLK_DIV2;
  RCC_ClkInitStruct.APB3CLKDivider = RCC_APB3_DIV2;
  RCC_ClkInitStruct.APB1CLKDivider = RCC_APB1_DIV2;
  RCC_ClkInitStruct.APB2CLKDivider = RCC_APB2_DIV2;
  RCC_ClkInitStruct.APB4CLKDivider = RCC_APB4_DIV2;

  if (HAL_RCC_ClockConfig(&RCC_ClkInitStruct, FLASH_LATENCY_4) != HAL_OK)
  {
    Error_Handler();
  }
}

void HAL_TIM_PeriodElapsedCallback(TIM_HandleTypeDef *htim)
{
  if (htim->Instance == TIM17)
  {
    HAL_IncTick();
  }
}

void Error_Handler(void)
{
  __disable_irq();
  while (1)
  {
  }
}

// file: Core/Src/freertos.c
/* USER CODE BEGIN Header */
/**
 ******************************************************************************
 * File Name          : freertos.c
 * Description        : Code for freertos applications
 ******************************************************************************
 * @attention
 *
 * <h2><center>&copy; Copyright (c) 2022 STMicroelectronics.
 * All rights reserved.</center></h2>
 *
 * This software component is licensed by ST under Ultimate Liberty license
 * SLA0044, the "License"; You may not use this file except in compliance with
 * the License. You may obtain a copy of the License at:
 *                             www.st.com/SLA0044
 *
 ******************************************************************************
 */
/* USER CODE END Header */

#include "FreeRTOS.h"
#include "task.h"
#include "main.h"
#include "cmsis_os.h"

/* USER CODE BEGIN Includes */
#include "dma.h"
#include "quadspi.h"
#include "usart.h"
#include "usb_device.h"
#include "gpio.h"
#include "usbd_cdc_if.h"
#include "shell_port.h"
#include "mdrtuslave.h"
#include "dwin.h"
#include "Flash.h"
#include "lte.h"
/* USER CODE END Includes */

/* USER CODE BEGIN PTD */
// GPIO_PinState State = GPIO_PIN_SET;
bool g_oSRunFlag = false;
Save_HandleTypeDef Save_Flash;
Save_User *puser = &Save_Flash.User;
// const uint8_t para_flash_area[128 * 1024 * 2U] __attribute__((at(UPDATE_SAVE_ADDRESS)));
/* USER CODE END PTD */

/* USER CODE BEGIN PD */
// EventGroupHandle_t Event_Handle = NULL;
Save_Param Save_InitPara = {
    .crc16 = 0xF168,
    .Ptank_max = 4.0F,
    .Ptank_min = 0.0F,
    .Pvap_outlet_max = 4.0F,
    .Pvap_outlet_min = 0.0F,
    .Pgas_soutlet_max = 4.0F,
    .Pgas_soutlet_min = 0.0F,
    .Ltank_max = 20.0F,
    .Ltank_min = 0.0F,
    .Ptoler_upper = 100.0F,
    .Ptoler_lower = 0.0F,
    .Ltoler_upper = 2.0F,
    // .Ltoler_lower = 0.5F,
    .PStank_supplement = 1.3F,
    .PSspf_start = 2.0F,
    .PSspf_stop = 1.8F,
    .PSvap_outlet_Start = 1.2F,
    .PSvap_outlet_stop = 1.1F,
    .Pback_difference = 1.8F,
    .Ptank_difference = 1.6F,
    .PPvap_outlet_Start = 2.1F,
    .PPvap_outlet_stop = 1.6F,
    .PPspf_start = 2.1F,
    .PPspf_stop = 1.9F,
    .Ptank_limit = 1.2F,
    .Ltank_limit = 2.0F,
    .Htank = 0.1F,
    .Rtank = 1.25F,
    .LEtank = 11.14F,
    .Dtank = 1.977F,

    .Error_Code = 0x0000,
    .User_Name = 0x07E6,
    .User_Code = 0x0522,
    .System_Version = SYSTEM_VERSION(),
    .System_Flag = 0xFFFFFFFF,
    .Slave_IRQ_Table.IRQ_Table_SetFlag = 0xFFFFFFFF,
    // .Update = 0xFFFFFFFF,
};
/* USER CODE END PD */

/* USER CODE BEGIN PM */
#define MASTER_TASK_BIT (0x001 << 0U)
#define RUN_TASK_BIT (0x001 << 1U)
#define WAVE_TASK_BIT (0x001 << 2U)
#define DWIN_TASK_BIT (0x001 << 3U)
#define ADC_TASK_BIT (0x001 << 4U)
#define EVENT_ALL_BIT (MASTER_TASK_BIT)
/* USER CODE END PM */

osThreadId ShellHandle;
osThreadId ScreenHandle;
osThreadId RS485Handle;
osThreadId WifiHandle;
osThreadId C4GHandle;
osThreadId MasterHandle;
osThreadId InterruptHandle;
osThreadId controlHandle;
osThreadId TransimtHandle;
osThreadId TreportHandle;
osMessageQId CodeQueueHandle;
osMessageQId UserQueueHandle;
osMessageQId SureQueueHandle;
osTimerId ReportHandle;
osTimerId ModbusHandle;
osMutexId shellMutexHandle;
osSemaphoreId Recive_CpuHandle;
osSemaphoreId Recive_Rs485Handle;
osSemaphoreId Recive_Rs232Handle;
osSemaphoreId Recive_WifiHandle;
osSemaphoreId Recive_LteHandle;
osSemaphoreId Code_SignalHandle;
osSemaphoreId Recive_UsbHandle;

void Shell_Task(void const *argument);
void Screen_Task(void const *argument);
void RS485_Task(void const *argument);
void Wifi_Task(void const *argument);
void C4G_Task(void const *argument);
void Master_Task(void const *argument);
void IRQ_Task(void const *argument);
void Control_Task(void const *argument);
void Transimt_Task(void const *argument);
void Report_Task(void const *argument);
void Report_Callback(void const *argument);
void Modbus_Callback(void const *argument);

extern void MX_USB_DEVICE_Init(void);
void MX_FREERTOS_Init(void); /* (MISRA C 2004 rule 8.1) */

/* GetIdleTaskMemory prototype (linked to static allocation support) */
void vApplicationGetIdleTaskMemory(StaticTask_t **ppxIdleTaskTCBBuffer, StackType_t **ppxIdleTaskStackBuffer, uint32_t *pulIdleTaskStackSize);

/* GetTimerTaskMemory prototype (linked to static allocation support) */
void vApplicationGetTimerTaskMemory(StaticTask_t **ppxTimerTaskTCBBuffer, StackType_t **ppxTimerTaskStackBuffer, uint32_t *pulTimerTaskStackSize);

/* Hook prototypes */
void vApplicationStackOverflowHook(xTaskHandle xTask, signed char *pcTaskName);
void vApplicationMallocFailedHook(void);

/* USER CODE BEGIN 4 */
__weak void vApplicationStackOverflowHook(xTaskHandle xTask, signed char *pcTaskName)
{
  /* Run time stack overflow checking is performed if
  configCHECK_FOR_STACK_OVERFLOW is defined to 1 or 2. This hook function is
  called if a stack overflow is detected. */
  shellPrint(Shell_Object, "%s is stack overflow!\r\n", pcTaskName);
}
/* USER CODE END 4 */

/* USER CODE BEGIN 5 */
__weak void vApplicationMallocFailedHook(void)
{
  /* vApplicationMallocFailedHook() will only be called if
  configUSE_MALLOC_FAILED_HOOK is set to 1 in FreeRTOSConfig.h. It is a hook
  function that will get called if a call to pvPortMalloc() fails.
  pvPortMalloc() is called internally by the kernel whenever a task, queue,
  timer or semaphore is created. It is also called by various parts of the
  demo application. If heap_1.c or heap_2.c are used, then the size of the
  heap available to pvPortMalloc() is defined by configTOTAL_HEAP_SIZE in
  FreeRTOSConfig.h, and the xPortGetFreeHeapSize() API function can be used
  to query the size of free heap space that remains (although it does not
  provide information on how the remaining heap might be fragmented). */
  shellPrint(Shell_Object, "memory allocation failed!\r\n");
}
/* USER CODE END 5 */

/* USER CODE BEGIN GET_IDLE_TASK_MEMORY */
static StaticTask_t xIdleTaskTCBBuffer;
static StackType_t xIdleStack[configMINIMAL_STACK_SIZE];

void vApplicationGetIdleTaskMemory(StaticTask_t **ppxIdleTaskTCBBuffer, StackType_t **ppxIdleTaskStackBuffer, uint32_t *pulIdleTaskStackSize)
{
  *ppxIdleTaskTCBBuffer = &xIdleTaskTCBBuffer;
  *ppxIdleTaskStackBuffer = &xIdleStack[0];
  *pulIdleTaskStackSize = configMINIMAL_STACK_SIZE;
  /* place for user code */
}
/* USER CODE END GET_IDLE_TASK_MEMORY */

/* USER CODE BEGIN GET_TIMER_TASK_MEMORY */
static StaticTask_t xTimerTaskTCBBuffer;
static StackType_t xTimerStack[configTIMER_TASK_STACK_DEPTH];

void vApplicationGetTimerTaskMemory(StaticTask_t **ppxTimerTaskTCBBuffer, StackType_t **ppxTimerTaskStackBuffer, uint32_t *pulTimerTaskStackSize)
{
  *ppxTimerTaskTCBBuffer = &xTimerTaskTCBBuffer;
  *ppxTimerTaskStackBuffer = &xTimerStack[0];
  *pulTimerTaskStackSize = configTIMER_TASK_STACK_DEPTH;
  /* place for user code */
}

/**
 * @brief	Background setting parameters will be written to the Modbus holding register
 * @details
 * @param	ps Point to the address of the first background parameter
 * @retval	None
 */
void Param_WriteBack(Save_HandleTypeDef *ps)
{
  // uint16_t len = sizeof(Save_Param) - sizeof(uint32_t) - sizeof(ps->Param.crc16);
  ps->Param.System_Flag = (*(__IO uint32_t *)UPDATE_SAVE_ADDRESS);
  /*Parameters are written to the mdbus hold register*/
  mdSTATUS ret = mdRTU_WriteHoldRegs(Slave1_Object, PARAM_BASE_ADDR, GET_PARAM_SITE(Save_Param, Slave_IRQ_Table, uint16_t),
                                     (mdU16 *)&ps->Param);
  /*Write user name and password*/
  // ret = mdRTU_WriteHoldRegs(Slave1_Object, MDUSER_NAME_ADDR, 2U, (mdU16 *)&ps->Param.User_Name);
  //   mdU16 temp_data[2U] = {(mdU16)CURRENT_SOFT_VERSION, (mdU16)((uint32_t)((*(__IO uint32_t *)UPDATE_SAVE_ADDRESS) >> 16U))};
  // #if defined(USING_DEBUG)
  //   shellPrint(Shell_Object, "version:%d, flag:%d.\r\n", temp_data[0], temp_data[1]);
  // #endif
  //   /*Write software version number and status*/
  //   ret = mdRTU_WriteHoldRegs(Slave1_Object, SOFT_VERSION_ADDR, 2U, temp_data);
  if (ret == mdFALSE)
  {
#if defined(USING_DEBUG)
    shellPrint(Shell_Object, "Parameter write to hold register failed!\r\n");
#endif
  }
}

/**
 * @brief	Report screen background parameters
 * @details
 * @param	pd:Dewin obj
 * @param sp:data pointer
 * @retval	NULL
 */
void Report_Backparam(pDwinHandle pd, Save_Param *sp)
{
  uint32_t actual_size = offsetof(Save_Param, Error_Code); // 29*szieof(float)
#if defined(USING_FREERTOS)
  float *pdata = (float *)CUSTOM_MALLOC(actual_size);
  if (!pdata)
    goto __exit;
#else
  float pdata[sizeof(Save_Param) - 1U];
#endif

  memcpy(pdata, sp, actual_size);
  for (float *p = pdata; p < pdata + actual_size / sizeof(float); p++)
  {
#if defined(USING_DEBUG)
    shellPrint(Shell_Object, "sp = %p,p = %p, *p = %.3f\r\n", sp, p, *p);
#endif
    Endian_Swap((uint8_t *)p, 0U, sizeof(float));
  }
  pd->Dw_Write(pd, PARAM_SETTING_ADDR, (uint8_t *)pdata, actual_size);

__exit:
  CUSTOM_FREE(pdata);
}

/**
 * @brief	Determine how the 4G module works
 * @details
 * @param	handler:modbus master/slave handle
 * @retval	true：MODBUS;fasle:shell
 */
bool Check_Mode(ModbusRTUSlaveHandler handler)
{
  ReceiveBufferHandle pB = handler->receiveBuffer;

  return (!!((pB->count == 1U) && (pB->buf[0] == ENTER_CODE)));
}

/**
 * @brief	Remote OTA
 * @details
 * @param handler:modbus master/slave handle
 * @param
 * @retval	NULL
 */
void OTA_Update(ModbusRTUSlaveHandler handler)
{
  uint32_t update_flag = 0;
  if (Check_Mode(handler))
  {
#if defined(USING_DEBUG)
    shellPrint(Shell_Object, "About to enter upgrade mode .......\r\n");
#endif
    /*Switch to the upgrade page*/
    if (Dwin_Object)
    {
#define Update_Page 0x11
      Dwin_Object->Dw_Page(Dwin_Object, Update_Page);
    }

    update_flag = (*(__IO uint32_t *)UPDATE_SAVE_ADDRESS);

    if (((update_flag & 0xFFFF0000) >> 16U) == UPDATE_APP1)
    {
      update_flag = (((uint32_t)UPDATE_APP2 << 16U) | UPDATE_CMD);
    }
    else
    {
      update_flag = (((uint32_t)UPDATE_APP1 << 16U) | UPDATE_CMD);
    }
    // update_flag = ((*(__IO uint32_t *)UPDATE_SAVE_ADDRESS) & 0xFFFF0000) | UPDATE_CMD;
    taskENTER_CRITICAL();
    FLASH_Write(UPDATE_SAVE_ADDRESS, (uint32_t *)&update_flag, sizeof(update_flag));
    taskEXIT_CRITICAL();
#define __RESET_SYSTEM
    {
      __set_FAULTMASK(1);
      NVIC_SystemReset();
    }
  }
  else
  {
    mdRTU_Handler(Slave1_Object);
  }
}

/**
 * @brief	Read the status of 4G module pins (work, net, link)
 * @details	13. Pelink, 15 hardware connection
 *          Affected by the size end, it only needs to be placed at the lower 8bit
 * @param	None
 * @retval	Three lamp states (8-10bit)
 */
static uint8_t Read_ATx_State(void)
{
#define PINX_NUM 5U
  GPIO_TypeDef *pGPIOx;
  uint16_t GPIO_Pinx;
  uint8_t status = 0, bit = 0;

  for (uint8_t i = 0; i < PINX_NUM; i++)
  {
    pGPIOx = i <= 2U ? LTE_LINK_GPIO_Port : WIFI_LINK_GPIO_Port;
    GPIO_Pinx = i > 1U ? (i == 2U ? LTE_LINK_Pin : (i == 3U ? WIFI_READY_Pin : WIFI_LINK_Pin)) : LTE_NET_Pin;
    /*The 1.8V level of link and net of 4G module matches
    with the 3.3 level of MCU, resulting in effective level reversal.*/
    bit = (uint32_t)(pGPIOx->IDR & GPIO_Pinx) ? 0U : 1U;
    status |= (uint8_t)(bit << i);
  }
#if defined(USING_DEBUG)
  // shellPrint(Shell_Object, "LTE_Status = 0x%x.\r\n", status);
#endif
  return status;
}

/* USER CODE END GET_TIMER_TASK_MEMORY */

void MX_FREERTOS_Init(void)
{
  /* USER CODE BEGIN Init */
  /* Create event flag group */
  // Event_Handle = xEventGroupCreate();
  Save_HandleTypeDef *ps = &Save_Flash;
  MX_FLASH_Init();
  /* USER CODE END Init */
  /* Create the mutex(es) */
  /* definition and creation of shellMutex */
  osMutexDef(shellMutex);
  shellMutexHandle = osMutexCreate(osMutex(shellMutex));

  /* Create the semaphores(s) */
  /* definition and creation of Recive_Cpu */
  osSemaphoreDef(Recive_Cpu);
  Recive_CpuHandle = osSemaphoreCreate(osSemaphore(Recive_Cpu), 1);

  /* definition and creation of Recive_Rs485 */
  osSemaphoreDef(Recive_Rs485);
  Recive_Rs485Handle = osSemaphoreCreate(osSemaphore(Recive_Rs485), 1);

  /* definition and creation of Recive_Rs232 */
  osSemaphoreDef(Recive_Rs232);
  Recive_Rs232Handle = osSemaphoreCreate(osSemaphore(Recive_Rs232), 1);

  /* definition and creation of Recive_Wifi */
  osSemaphoreDef(Recive_Wifi);
  Recive_WifiHandle = osSemaphoreCreate(osSemaphore(Recive_Wifi), 1);

  /* definition and creation of Recive_Lte */
  osSemaphoreDef(Recive_Lte);
  Recive_LteHandle = osSemaphoreCreate(osSemaphore(Recive_Lte), 1);

  /* definition and creation of Code_Signal */
  osSemaphoreDef(Code_Signal);
  Code_SignalHandle = osSemaphoreCreate(osSemaphore(Code_Signal), 1);

  /* definition and creation of Recive_Usb */
  osSemaphoreDef(Recive_Usb);
  Recive_UsbHandle = osSemaphoreCreate(osSemaphore(Recive_Usb), 1);

  /* USER CODE BEGIN RTOS_SEMAPHORES */
  /* add semaphores, ... */
  MX_ShellInit(Shell_Object);
  MX_ModbusInit();
  if (Slave1_Object)
  {
    __HAL_UART_ENABLE_IT(&huart1, UART_IT_IDLE);
    /*DMA buffer must point to an entity address!!!*/
    HAL_UART_Receive_DMA(&huart1, mdRTU_Recive_Buf(Slave1_Object), MODBUS_PDU_SIZE_MAX);
    __HAL_UART_ENABLE_IT(&huart5, UART_IT_IDLE);
    /*DMA buffer must point to an entity address!!!*/
    HAL_UART_Receive_DMA(&huart5, mdRTU_Recive_Buf(Slave1_Object), MODBUS_PDU_SIZE_MAX);
    __HAL_UART_ENABLE_IT(&huart2, UART_IT_IDLE);
    /*DMA buffer must point to an entity address!!!*/
    HAL_UART_Receive_DMA(&huart2, mdRTU_Recive_Buf(Slave1_Object), MODBUS_PDU_SIZE_MAX);
    Slave1_Object->receiveBuffer->count = 0U;
  }
  if (Slave2_Object)
  {
    __HAL_UART_ENABLE_IT(&huart3, UART_IT_IDLE);
    /*DMA buffer must point to an entity address!!!*/
    HAL_UART_Receive_DMA(&huart3, mdRTU_Recive_Buf(Slave2_Object), MODBUS_PDU_SIZE_MAX);
    Slave2_Object->receiveBuffer->count = 0U;
  }
  MX_DwinInit();
  if (Dwin_Object)
  {
    __HAL_UART_ENABLE_IT(&huart4, UART_IT_IDLE);
    /*DMA buffer must point to an entity address!!!*/
    HAL_UART_Receive_DMA(&huart4, Dwin_Recive_Buf(Dwin_Object), Dwin_Rx_Size(Dwin_Object));
    *Dwin_Object->Uart.pRxCount = 0U;
  }
  FLASH_Read(PARAM_SAVE_ADDRESS, &ps->Param, sizeof(Save_Param));
  // HAL_FLASH_Unlock();
  // if (__HAL_FLASH_GET_FLAG(FLASH_SR_SNECCERR))
  // {
  //   __HAL_FLASH_CLEAR_FLAG(FLASH_SR_SNECCERR);
  // }
  // HAL_FLASH_Lock();
  /*Must be 4 byte aligned!!!*/
  uint16_t crc16 = Get_Crc16((uint8_t *)&ps->Param, sizeof(Save_Param) - sizeof(ps->Param.crc16), 0xFFFF);
#if defined(USING_DEBUG)
  // shellPrint(Shell_Object, "ps->Param.flag = 0x%x\r\n", ps->Param.flag);
  shellPrint(Shell_Object, "ps->Param.crc16 = 0x%x, crc16 = 0x%x.\r\n", ps->Param.crc16, crc16);
#endif
  if (crc16 != ps->Param.crc16)
  {
    Save_InitPara.crc16 = Get_Crc16((uint8_t *)&Save_InitPara, sizeof(Save_Param) - sizeof(Save_InitPara.crc16), 0xFFFF);
    memcpy(&ps->Param, &Save_InitPara, sizeof(Save_Param));
    FLASH_Write(PARAM_SAVE_ADDRESS, (uint32_t *)&Save_InitPara, sizeof(Save_Param));
#if defined(USING_DEBUG)
    shellPrint(Shell_Object, "Save_InitPara.crc16 = 0x%x,First initialization of flash parameters!\r\n", Save_InitPara.crc16);
#endif
    /*Initial 4G module or Wifi*/
    MX_AtInit();
    if (Lte_Object)
    {
      Lte_Object->AT_SetDefault(Lte_Object);
      Lte_Object->Free_AtObject(&Lte_Object);
    }
    if (Wifi_Object)
    {
      Wifi_Object->AT_SetDefault(Wifi_Object);
      Wifi_Object->Free_AtObject(&Wifi_Object);
    }
  }
  /*Check whether the board information has been initialized*/
  if (ps->Param.Slave_IRQ_Table.IRQ_Table_SetFlag != SAVE_SURE_CODE)
  {
#if defined(USING_DEBUG)
    shellPrint(Shell_Object, "Please initialize board information!\r\n");
#endif
#define CONFIG_CARD_INFO_PAGE 29U
    /*The screen forcibly jumps to the image page of the board information configuration*/
    Dwin_Object->Dw_Page(Dwin_Object, CONFIG_CARD_INFO_PAGE);
  }
  else
  {
    if (IRQ_Table.pReIRQ && IRQ_Table.pIRQ)
    {
      /*Copy flash parameters to the application area*/
      // memcpy(IRQ_Table.pReIRQ, ps->Param.Slave_IRQ_Table.ReIRQ, sizeof(ps->Param.Slave_IRQ_Table.ReIRQ));
      memcpy(IRQ_Table.pIRQ, ps->Param.Slave_IRQ_Table.IRQ, sizeof(ps->Param.Slave_IRQ_Table.IRQ));
      IRQ_Table.TableCount = ps->Param.Slave_IRQ_Table.TableCount;
#if defined(USING_DEBUG)
      shellPrint(Shell_Object, "\r\nIRQ_Table Information:\r\nSlaveId\t\tPriority\t\tType\t\tNumber\r\n");
      for (uint8_t i = 0; i < CARD_NUM_MAX; i++)
      {
        shellPrint(Shell_Object, "0x%x\t\t0x%x\t\t\t0x%x\t\t%d\r\n", IRQ_Table.pIRQ[i].SlaveId, IRQ_Table.pIRQ[i].Priority,
                   IRQ_Table.pIRQ[i].TypeCoding, IRQ_Table.pIRQ[i].Number);
      }
#endif
    }
  }
  /*Parameters are stored in the holding register*/
  Param_WriteBack(ps);
  /*Turn off the global interrupt in bootloader, and turn it on here*/
  // __set_FAULTMASK(0);
  /*Solve the problem that the background data cannot be received due to the unstable power supply when the Devon screen is turned on*/
  // HAL_Delay(2000);
  // Report_Backparam(Dwin_Object, &ps->Param);
  /* USER CODE END RTOS_SEMAPHORES */

  /* Create the timer(s) */
  /* definition and creation of Report */
  osTimerDef(Report, Report_Callback);
  ReportHandle = osTimerCreate(osTimer(Report), osTimerPeriodic, NULL);

  /* definition and creation of Modbus */
  osTimerDef(Modbus, Modbus_Callback);
  ModbusHandle = osTimerCreate(osTimer(Modbus), osTimerPeriodic, NULL);

  /* USER CODE BEGIN RTOS_TIMERS */
  /* start timers, add new ones, ... */

#define REPORRT_TIMERS 800U
  osTimerStart(ReportHandle, REPORRT_TIMERS);
  osTimerStart(ModbusHandle, 1000U);
  /* USER CODE END RTOS_TIMERS */

  /* Create the queue(s) */
  /* definition and creation of CodeQueue */
  osMessageQDef(CodeQueue, 16, uint16_t);
  CodeQueueHandle = osMessageCreate(osMessageQ(CodeQueue), NULL);

  /* definition and creation of UserQueue */
  osMessageQDef(UserQueue, 4, Save_User);
  UserQueueHandle = osMessageCreate(osMessageQ(UserQueue), NULL);

  /* definition and creation of SureQueue */
  osMessageQDef(SureQueue, 16, IRQ_Request);
  SureQueueHandle = osMessageCreate(osMessageQ(SureQueue), NULL);

  /* Create the thread(s) */
  /* definition and creation of Shell */
  osThreadDef(Shell, Shell_Task, osPriorityLow, 0, 256);
  ShellHandle = osThreadCreate(osThread(Shell), (void *)&shell);

  /* definition and creation of Screen */
  osThreadDef(Screen, Screen_Task, osPriorityBelowNormal, 0, 256);
  ScreenHandle = osThreadCreate(osThread(Screen), (void *)Dwin_Object);

  /* definition and creation of RS485 */
  osThreadDef(RS485, RS485_Task, osPriorityLow, 0, 128);
  RS485Handle = osThreadCreate(osThread(RS485), (void *)Slave2_Object);

  /* definition and creation of Wifi */
  osThreadDef(Wifi, Wifi_Task, osPriorityLow, 0, 256);
  WifiHandle = osThreadCreate(osThread(Wifi), (void *)Slave1_Object);

  /* definition and creation of C4G */
  osThreadDef(C4G, C4G_Task, osPriorityLow, 0, 256);
  C4GHandle = osThreadCreate(osThread(C4G), (void *)Slave1_Object);

  /* definition and creation of Master */
  osThreadDef(Master, Master_Task, osPriorityHigh, 0, 256);
  MasterHandle = osThreadCreate(osThread(Master), (void *)Slave1_Object);

  /* definition and creation of Interrupt */
  osThreadDef(Interrupt, IRQ_Task, osPriorityRealtime, 0, 256);
  InterruptHandle = osThreadCreate(osThread(Interrupt), (void *)&IRQ_Table);

  /* definition and creation of control */
  osThreadDef(control, Control_Task, osPriorityNormal, 0, 512);
  controlHandle = osThreadCreate(osThread(control), (void *)&Save_Flash);

  /* definition and creation of Transimt */
  osThreadDef(Transimt, Transimt_Task, osPriorityHigh, 0, 512);
  TransimtHandle = osThreadCreate(osThread(Transimt), (void *)&IRQ_Table);

  /* definition and creation of Treport */
  osThreadDef(Treport, Report_Task, osPriorityIdle, 0, 512);
  TreportHandle = osThreadCreate(osThread(Treport), (void *)&Save_Flash);

}

void Shell_Task(void const *argument)
{
  /* init code for USB_DEVICE */
  MX_USB_DEVICE_Init();
  /* USER CODE BEGIN Shell_Task */
  g_oSRunFlag = true;
  /* Infinite loop */
  for (;;)
  {
#if defined(USING_USB)
    /*https://www.cnblogs.com/w-smile/p/11333950.html*/
    if (osOK == osSemaphoreWait(Recive_UsbHandle, osWaitForever))
    {
      Shell *shell = (Shell *)argument;
      extern USBD_HandleTypeDef hUsbDeviceFS;
      if (Usb.pRxbuf)
      {
        for (uint8_t *p = Usb.pRxbuf; p < Usb.pRxbuf + Usb.counts;)
          shellHandler(shell, *p++);
        Usb.counts = 0U;
        USBD_CDC_SetRxBuffer(&hUsbDeviceFS, Usb.pRxbuf);
        USBD_CDC_ReceivePacket(&hUsbDeviceFS);
      }
    }
    // osDelay(1000);
#else
    shellTask((void *)argument);
#endif
  }
  /* USER CODE END Shell_Task */
}

void Screen_Task(void const *argument)
{
  /* USER CODE BEGIN Screen_Task */
  pDwinHandle pDewin = (pDwinHandle)argument;
  // osDelay(5);
  // /*Parameters are stored in the holding register*/
  // Param_WriteBack(&Save_Flash);
  /*Solve the problem of screen background parameter delay*/
  osDelay(3000);
  Report_Backparam(Dwin_Object, &Save_Flash.Param);
  /* Infinite loop */
  for (;;)
  {
    /*https://www.cnblogs.com/w-smile/p/11333950.html*/
    if ((osOK == osSemaphoreWait(Recive_Rs232Handle, osWaitForever)) && pDewin)
    {
      /*Close the reporting timer*/
      osTimerStop(ReportHandle);
      /*Suspend reporting task*/
      osThreadSuspend(TreportHandle);
      Dwin_Handler(pDewin);
      /*Resume reporting task*/
      osThreadResume(TreportHandle);
      // xTimerReset(ReportHandle, 1U);
      osTimerStart(ReportHandle, REPORRT_TIMERS);
#if defined(USING_DEBUG)
      // shellPrint(Shell_Object, "Screen received a packet of data .\r\n");
#endif
    }
  }
  /* USER CODE END Screen_Task */
}

void RS485_Task(void const *argument)
{
  /* USER CODE BEGIN RS485_Task */
  struct ModbusRTUSlave *pSlave = (struct ModbusRTUSlave *)argument;
  /* Infinite loop */
  for (;;)
  {
    /*https://www.cnblogs.com/w-smile/p/11333950.html*/
    if ((osOK == osSemaphoreWait(Recive_Rs485Handle, osWaitForever)) && pSlave)
    {
      pSlave->uartId = 0x03;
      mdRTU_Handler(pSlave);
#if defined(USING_DEBUG)
      shellPrint(Shell_Object, "RS485 received a packet of data .\r\n");
#endif
    }
  }
  /* USER CODE END RS485_Task */
}

void Wifi_Task(void const *argument)
{
  /* USER CODE BEGIN Wifi_Task */
  struct ModbusRTUSlave *pSlave = (struct ModbusRTUSlave *)argument;
  /* Infinite loop */
  for (;;)
  {
    /*https://www.cnblogs.com/w-smile/p/11333950.html*/
    if ((osOK == osSemaphoreWait(Recive_WifiHandle, osWaitForever)) && pSlave)
    {
      pSlave->uartId = 0x05;
      // mdRTU_Handler(Slave1_Object);
      OTA_Update(pSlave);
#if defined(USING_DEBUG)
      shellPrint(Shell_Object, "Wifi received a packet of data .\r\n");
#endif
    }
  }
  /* USER CODE END Wifi_Task */
}

void C4G_Task(void const *argument)
{
  /* USER CODE BEGIN C4G_Task */
  struct ModbusRTUSlave *pSlave = (struct ModbusRTUSlave *)argument;
  /* Infinite loop */
  for (;;)
  {
    /*https://www.cnblogs.com/w-smile/p/11333950.html*/
    if ((osOK == osSemaphoreWait(Recive_LteHandle, osWaitForever)) && pSlave)
    {
      pSlave->uartId = 0x02;
      // mdRTU_Handler(Slave1_Object);
      OTA_Update(pSlave);
#if defined(USING_DEBUG)
      shellPrint(Shell_Object, "4G received a packet of data .\r\n");
#endif
    }
  }
  /* USER CODE END C4G_Task */
}

void Master_Task(void const *argument)
{
  /* USER CODE BEGIN Master_Task */
#define MASTER_OBJECT Slave1_Object
#define ULONG_MAX 0xFFFFFFFF
  uint32_t target_slave_id = 0;
  struct ModbusRTUSlave *pMaster = (struct ModbusRTUSlave *)argument;

  /* Infinite loop */
  for (;;)
  {
    /*https://www.cnblogs.com/w-smile/p/11333950.html*/
    if ((osOK == osSemaphoreWait(Recive_CpuHandle, osWaitForever)) && pMaster)
    {
      // if (xQueueReceive(SureQueueHandle, &target_slave_id, osWaitForever) == pdPASS)
      // {
      //   pMaster->uartId = 0x01;
      //   pMaster->portRTUMasterHandle(pMaster, (mdU8)target_slave_id);
      // }
      // osThreadSuspend(InterruptHandle);
      // osThreadSuspend(TransimtHandle);
      pMaster->uartId = 0x01;
      pMaster->portRTUMasterHandle(pMaster, (mdU8)target_slave_id);
      // osThreadResume(InterruptHandle);
      // osThreadResume(TransimtHandle);
      xTaskNotifyWait(0x00,             /* Don't clear any notification bits on entry. */
                      ULONG_MAX,        /* Reset the notification value to 0 on exit. */
                      &target_slave_id, /* Notified value pass out in ulNotifiedValue. */
                      osWaitForever);   /* Block indefinitely. */
    }
  }
  /* USER CODE END Master_Task */
}

/* USER CODE BEGIN Header_IRQ_Task */
/**
 * @brief Function implementing the Interrupt thread.
 * @param argument: Not used
 * @retval None
 */
__inline uint8_t Get_InterruptSite(uint16_t id)
{
#define ERROR_INTERRUPT 0xFF
  uint8_t site = 0x00;

  if ((id == 0U) || ((id % 2U) && (id != 0x01)))
    return ERROR_INTERRUPT;

  while (id != 0x01)
  {
    id >>= 1U, site++;
  }
  return site;
}
/**
 * @brief Function implementing the Interrupt thread.
 * @param argument: Not used
 * @retval None
 */
/* USER CODE END Header_IRQ_Task */
void IRQ_Task(void const *argument)
{
  /* USER CODE BEGIN IRQ_Task */
  uint16_t interrupt_id;
  Slave_IRQTableTypeDef *sp_irq = (Slave_IRQTableTypeDef *)argument;
  IRQ_Request *p_current = NULL;
  /* Infinite loop */
  for (;;)
  {
    /*It is detected that the slave has issued an interrupt request*/
    if (xQueueReceive(CodeQueueHandle, &interrupt_id, osWaitForever) == pdPASS)
    {
      p_current = &sp_irq->pReIRQ[sp_irq->SiteCount];
#if defined(USING_DEBUG)
      // shellPrint(Shell_Object, "Note: Generate an interrupt: 0x%x.\r\n", interrupt_id);
#endif
      /*Separate the interrupt number and count the interrupt source*/
      // while ((interrupt_id) && (sp_irq->SiteCount < CARD_NUM_MAX) &&
      //        /*Ensure that the previous round of interrupt has been handled correctly*/
      //        (!p_current->flag))
      while ((interrupt_id) && (sp_irq->SiteCount++ < CARD_NUM_MAX))
      /*Ensure that the previous round of interrupt has been handled correctly*/
      {
        p_current->site = interrupt_id;
        interrupt_id &= interrupt_id - 1U;
        p_current->site -= interrupt_id;
        p_current->flag = true;
        /*Assign priority to the current interrupt source*/
        if (sp_irq->TableCount)
        {
          for (IRQ_Code *p = sp_irq->pIRQ; p < sp_irq->pIRQ + sp_irq->TableCount; p++)
          {
            if ((uint8_t)(pow(2.0, p->SlaveId)) == p_current->site)
            {
              p_current->Priority = p->Priority;
              break;
            }
          }
        }
// sp_irq->SiteCount++;
#if defined(USING_DEBUG)
        // shellPrint(Shell_Object, "Note: re_irq[%d]_id = 0x%x.\r\n", sp_irq->SiteCount, p_current->site);
#endif
        // p_current = &sp_irq->pReIRQ[++sp_irq->SiteCount];
        p_current++;
      }
      /*Record in the interrupt list. When the board sends an
      interrupt request for the second time, it will be prioritized*/
      if (sp_irq->TableCount && (sp_irq->SiteCount > 1U))
      {
        Quick_Sort(sp_irq->pReIRQ, sp_irq->SiteCount);
      }
      for (uint16_t i = 0; i < sp_irq->SiteCount; i++)
      {
        xQueueSend(SureQueueHandle, &sp_irq->pReIRQ[i], 0);
      }
      sp_irq->SiteCount = 0;
    }
  }
  /* USER CODE END IRQ_Task */
}

/* USER CODE BEGIN Header_Control_Task */
/**
 * @brief  Check whether the status of each switch changes
 * @param  p_current current state
 * @param  p_last Last status
 * @param  size  Detection length
 * @retval true/false
 */
bool Check_Vx_State(mdBit *p_current, mdBit *p_last, uint8_t size)
{
  bool ret = false;
  if (p_current && p_last && size)
  {
    for (uint8_t i = 0; i < size; i++)
    {
      if (p_current[i] != p_last[i])
      {
        p_last[i] = p_current[i];
        ret = true;
      }
    }

    // for (mdBit *p = p_current, *q = p_last; p < p_current + size; p++, q++)
    // {
    //   if (*p != *q)
    //   {
    //     *q = *p;
    //     ret = true;
    //   }
    // }
  }
  return ret;
}

/**
 * @brief Function implementing the control thread.
 * @param argument: Not used
 * @retval None
 */
#define DELAY_TIMES 5U
/* USER CODE END Header_Control_Task */
void Control_Task(void const *argument)
{
  /* USER CODE BEGIN Control_Task */
  mdBit sbit = mdLow, mode = mdLow, bitx = mdLow, rbit = mdLow;
  mdSTATUS ret = mdFALSE;
  mdBit wbit[VX_SIZE];
  float Ptank = 0, Pcarburetor = 0;
  static Soft_Timer_HandleTypeDef timer[] = {
      {.counts = 0, .flag = false},
      {.counts = 0, .flag = false},
  };
  // bool flag_group[] = {false, false};
  Save_HandleTypeDef *ps = (Save_HandleTypeDef *)argument;
  Save_User usinfo;
  static bool mutex_flag[] = {false, false, false};
  /*Solve the problem of screen background parameter delay*/
  // osDelay(2000);
  // Report_Backparam(Dwin_Object, &ps->Param);
  /* Infinite loop */
  for (;;)
  {
    sbit = mdLow;
    uint16_t error_code = 0;
    /*Initialize WBIT*/
    memset(wbit, false, VX_SIZE);
    /*The default state of the initialization electric valve is off*/
    Close_Qx(5U), Open_Qx(6U), Close_Qx(7U), Open_Qx(8U);
#define __USER_CONTRL_PARAMTER_CALCULATION
    {
      ret = mdRTU_ReadInputRegisters(Slave1_Object, INPUT_ANALOG_START_ADDR, BX_SIZE * 2U, (mdU16 *)&ps->User);
      if (ret == mdFALSE)
      {
#if defined(USING_DEBUG)
        shellPrint(Shell_Object, "Failed to read input register!\r\n");
#endif
        goto __exit;
      }
      mdBit enable_sate[] = {false, false};
      /*Read whether the remote enables the secondary sensor to participate in the control*/
      ret = mdRTU_ReadCoils(Slave1_Object, ENABLE_S_PTANK_ADDR, sizeof(enable_sate) / sizeof(mdBit), enable_sate);
      if (ret == mdFALSE)
      {
#if defined(USING_DEBUG)
        shellPrint(Shell_Object, "enable_sate[0] = 0x%d,enable_sate[1] = 0x%d\r\n", enable_sate[0], enable_sate[1]);
#endif
        goto __no_action;
      }
      // taskENTER_CRITICAL();
      // for (float *p = &ps->User.Ptank_M, *pu = &ps->Param.Ptank_max, *pinfo = (float *)&usinfo;
      //      p < &ps->User.Ptank_M + BX_SIZE; p++, pu += 2U, pinfo++)
      for (float *p = &ps->User.Ptank_M, *pu = &ps->Param.Ptank_max, *pinfo = (float *)&usinfo;
           p < &ps->User.Ptank_M + BX_SIZE; p++, pinfo++)
      {
#define ERROR_BASE_CODE 0x02
        uint8_t site = p - &ps->User.Ptank_M;
#if defined(USING_DEBUG)
        // shellPrint(Shell_Object, "R_Current[0x%X] = %.3f\r\n", p, *p);
#endif
        /*User sensor access error check*/
#define ERROR_CHECK
        {
          if (!error_code)
          {
            error_code = *p <= 0.0F ? (3U * site + ERROR_BASE_CODE) : (*p < CURRENT_LOWER ? (3U * site + ERROR_BASE_CODE + 1U) : (*p > (CURRENT_LOWER + CURRENT_UPPER + 1.0F) ? (3U * site + ERROR_BASE_CODE + 2U) : 0));
          }
        }
        if (p < &ps->User.Ltank)
        {
          *p = Get_Target(*p, *pu, *(pu + 1U));
          pu += 2U;
        }
        else
        {
          *p = (p == &ps->User.Ptank_S) ? Get_Target(*p, ps->Param.Ptank_max, ps->Param.Ptank_min)
               : (p == &ps->User.Ltank) ? Get_Ptank_Level(Get_Target(*p, ps->Param.Ltank_max, ps->Param.Ltank_min),
                                                          ps->Param.Htank, ps->Param.Rtank, ps->Param.LEtank)
                                        : Get_Target(*p, ps->Param.Ptoler_upper, ps->Param.Ptoler_lower);
        }
        /*Convert analog signal into physical quantity*/
        // *p = Get_Target(*p, *pu, *(pu + 1U));
        *p = *p <= 0.0F ? 0 : *p;
        *pinfo = *p;
#if defined(USING_DEBUG)
        // shellPrint(Shell_Object, "max = %.3f,min = %.3f, C_Value[0x%p] = %.3fMpa/M3\r\n", *pu, *(pu + 1U), p, *p);
#endif
      }
      ps->Param.Error_Code = error_code;
#define __Enable_Secondary_Sensor
      {
        Ptank = enable_sate[0] ? ps->Param.Error_Code = 0, ps->User.Ptank_S : ps->User.Ptank_M;
        Pcarburetor = enable_sate[1] ? ps->Param.Error_Code = 0, ps->User.Pgas_soutlet : ps->User.Pvap_outlet;
      }
      // taskEXIT_CRITICAL();
      if (xQueueSend(UserQueueHandle, &usinfo, 2) != pdPASS)
      // if (osMailPut(UserQueueHandle, &usinfo) != osOK)
      {
#if defined(USING_DEBUG)
        shellPrint(Shell_Object, "Error: Failed to send user parameters!\r\n");
#endif
      }
    }
    // goto __no_action;
#if defined(USING_DEBUG)
    // shellPrint(Shell_Object, "ps->User.Ptank = %.3f\r\n", ps->User.Ptank);
#endif
    rbit = mdLow;
    /*Read start signal:0-N,As long as one start signal is valid, it is valid*/
    for (uint8_t i = 0; i < START_SIGNAL_MAX; i++)
    {
      ret = mdRTU_ReadInputCoil(Slave1_Object, INPUT_DIGITAL_START_ADDR + i, bitx);
      sbit += bitx;
      rbit |= (uint8_t)(bitx << i);
#if defined(USING_DEBUG)
      shellPrint(Shell_Object, "bitx[%d] = 0x%d\r\n", i, bitx);
#endif
      /*When the start signal is valid, the corresponding user valve is also valid.*/
#define __OPEN_USER_VALVE
      {
        // wbit[USER_COIL_OFFSET + i] = bitx;
      }
      if (ret == mdFALSE)
      {
#if defined(USING_DEBUG)
        shellPrint(Shell_Object, "IN_D[%d] = 0x%d\r\n", INPUT_DIGITAL_START_ADDR, sbit);
#endif
        goto __no_action;
      }
    }
    /*Manual mode management highest authority*/
    ret = mdRTU_ReadCoil(Slave1_Object, M_MODE_ADDR, mode);
    if (ret == mdFALSE)
    {
#if defined(USING_DEBUG)
      shellPrint(Shell_Object, "Mode[%d] = 0x%d\r\n", INPUT_DIGITAL_START_ADDR, mode);
#endif
      goto __no_action;
    }
    if (mode == mdHigh)
    {
#if defined(USING_DEBUG)
      shellPrint(Shell_Object, "@Note: Manual mode startup, automatic management failure!\r\n");
#endif
      /*Clear error codes*/
      ps->Param.Error_Code = 0;
      goto __exit;
    }
    /*Safe operation guarantee*/
#define SAFETY
    {
      if ((Ptank <= ps->Param.Ptank_limit) || (ps->User.Ltank <= ps->Param.Ltank_limit) ||
          (ps->Param.Error_Code))
      {
/*close Q0、Q1、Q3、Q4*/
// Close_Qx(0U), Close_Qx(1U), Close_Qx(3U), Close_Qx(4U);
/*reset timer*/
#if (USING_USERTIMER0)
        Reset_SoftTimer(&timer[0U], T_5S);
#endif
#if (USING_USERTIMER1)
        Reset_SoftTimer(&timer[1U], T_5S); //######
#endif
#if defined(USING_DEBUG_APPLICATION)
        shellPrint(Shell_Object, "@SAF: close Q0 Q1 Q3 Q4 Q5 Q7 open Q6 Q8.\r\n");
#endif
        goto __no_action;
      }
    }
#if defined(USING_DEBUG_APPLICATION)
    shellPrint(Shell_Object, "sbit = 0x%d\r\n", sbit);
#endif
    /*Start mode: The sbit value is valid if it is not 0.*/
    if (sbit)
    {
#define D1
      {
        /*close Q3*/
        // Close_Qx(3U);
#if defined(USING_DEBUG_APPLICATION)
        shellPrint(Shell_Object, "@D1-1: close Q3.\r\n");
#endif
      }
#define A1
      {
#if defined(USING_DEBUG_APPLICATION)
        // shellPrint(Shell_Object, "ps->User.Ptank = %.3f, ps->Param.PSspf_start = %.3f\r\n", ps->User.Ptank, ps->Param.PSspf_start);
#endif
        /*The pressure of the storage tank is protected in the safe mode,
        as long as the outlet pressure conditions of the vaporizer are met here*/
        if (Pcarburetor > ps->Param.PSvap_outlet_Start)
        {
#if (USING_USERTIMER0)
          SoftTimer_IsTrue(&timer[0U]); //#######
#endif
#if (USING_USERTIMER1)
          SoftTimer_IsTrue(&timer[1U]); //#######
#endif
          (rbit & 0x03) ? Open_Qx(5U), Close_Qx(6U) : false;
          (rbit & 0x04) ? Open_Qx(7U), Close_Qx(8U) : false;
#if defined(USING_DEBUG_APPLICATION)
          shellPrint(Shell_Object, "@A1-1: open Q5 or Q7;close Q6 or Q8.\r\n");
#endif
        }
        (Ptank >= ps->Param.PSspf_start)  ? mutex_flag[0] = true
        : (Ptank <= ps->Param.PSspf_stop) ? mutex_flag[0] = false
                                          : false;
        /*Pressure relief*/
        if (mutex_flag[0])
        {
          Open_Qx(1U);
#if (USING_USERTIMER0)
          /*reset timer*/
          // Reset_SoftTimer(&timer[0U], T_5S);
#endif
#if defined(USING_DEBUG_APPLICATION)
          shellPrint(Shell_Object, "@A1-2: open Q1 Q5 or Q7;close Q0 Q6 or Q8.\r\n");
#endif
          goto __no_action;
        }
        else
        {
#if defined(USING_DEBUG_APPLICATION)
          shellPrint(Shell_Object, "@A1-3: open Q0;close Q1 Q3.\r\n");
#endif
        }
      }
#define B1C1
      {
        if (Pcarburetor >= ps->Param.PSvap_outlet_Start)
        {
          // SoftTimer_IsTrue(&timer[1U]); //#######
          /*open V1 、close V2*/
          Open_Qx(0U);
#if defined(USING_DEBUG_APPLICATION)
          shellPrint(Shell_Object, "@B1C1-1: open Q0 close Q1\r\n");
#endif
#if (USING_USERTIMER0)
          Set_SoftTimer_Count(&timer[0U], T_5S); //#####
#endif
#if (USING_USERTIMER1)
          Set_SoftTimer_Flag(&timer[1U], false); //######
#endif
              // SoftTimer_IsTrue(&timer[0U]);
          /*open outlet valve*/
          // (rbit & 0x03) ? Open_Qx(5U), Close_Qx(6U) : false;
          // (rbit & 0x04) ? Open_Qx(7U), Close_Qx(8U) : false;
#if defined(USING_DEBUG_APPLICATION)
          shellPrint(Shell_Object, "@B1C1-2: open Q5 or Q7 Close Q6 or Q8.\r\n");
#endif
        }
        else if (Pcarburetor <= ps->Param.PSvap_outlet_stop &&
                 Ptank > ps->Param.PStank_supplement)
        {
#if (USING_USERTIMER0)
          /*reset timer*/
          Reset_SoftTimer(&timer[0U], T_5S);
#endif
#if (USING_USERTIMER1)
          Set_SoftTimer_Count(&timer[1U], T_5S); //#######
#endif
          /*close Q0 and outlet valve*/
          Open_Qx(1U);
#if defined(USING_DEBUG_APPLICATION)
          shellPrint(Shell_Object, "@B1C1-3: open  Q1  Q5 or Q7;close Q0 Q6 or Q8.\r\n");
#endif
        }
      }
      /*Ensure that after the startup mode is switched to the shutdown mode*/
      mutex_flag[1] ? mutex_flag[1] = false : false;
      mutex_flag[2] ? mutex_flag[2] = false : false;
    }
    /*stop mode*/
    else
    {
#if (USING_USERTIMER0)
      /*clear flag*/
      Reset_SoftTimer(&timer[0U], T_5S);
#endif
#if (USING_USERTIMER1)
      Reset_SoftTimer(&timer[1U], T_5S); //######
#endif
      /*Check whether the pressure relief operation is on*/
      mutex_flag[0] ? mutex_flag[0] = false : false;
#define A2
      {
        // if (((Pcarburetor - Ptank) >= ps->Param.Pback_difference) && (Ptank < ps->Param.Ptank_difference))
        if (Pcarburetor > ps->Param.Pback_difference && (Ptank < ps->Param.Ptank_difference))
        {
          /*open Q1*/
          Open_Qx(1U);
#if defined(USING_DEBUG_APPLICATION)
          shellPrint(Shell_Object, "@A2-1: open Q1.\r\n");
#endif
        }
        else
        {
          /*Close Q1*/
          // Close_Qx(1U);
#if defined(USING_DEBUG_APPLICATION)
          shellPrint(Shell_Object, "@A2-2: Close Q1.\r\n");
#endif
        }
      }
#define B2
      {
        (Pcarburetor >= ps->Param.PPvap_outlet_Start)  ? mutex_flag[1] = true
        : (Pcarburetor <= ps->Param.PPvap_outlet_stop) ? mutex_flag[1] = false
                                                       : false;
        if (mutex_flag[1])
        {
          Open_Qx(5U), Close_Qx(6U);
          Open_Qx(4U);
#if defined(USING_DEBUG_APPLICATION)
          shellPrint(Shell_Object, "@B2-1: open Q4 Q5 or Q7;close Q1 Q6 or Q8.\r\n");
#endif
        }
        else
        {
#if defined(USING_DEBUG_APPLICATION)
          shellPrint(Shell_Object, "@B2-2: open Q5 or Q7 close Q4 Q6 or Q8.\r\n");
#endif
        }
      }
#define C2
      {
        (Ptank >= ps->Param.PPspf_start)  ? mutex_flag[2] = true
        : (Ptank <= ps->Param.PPspf_stop) ? mutex_flag[2] = false
                                          : false;
        if (mutex_flag[2])
        {
          Open_Qx(3U);
#if defined(USING_DEBUG_APPLICATION)
          shellPrint(Shell_Object, "@C2-1: open Q3.\r\n");
#endif
        }
        else
        {
#if defined(USING_DEBUG_APPLICATION)
          shellPrint(Shell_Object, "@C2-2: close Q3.\r\n");
#endif
        }
      }
#define D2
      {
        /*close V1*/
        // Close_Qx(0U);
#if defined(USING_DEBUG_APPLICATION)
        shellPrint(Shell_Object, "@D2-1: close Q0.\r\n");
#endif
      }
    }
  __no_action:
#if defined(USING_DEBUG_APPLICATION)
    // for (uint16_t i = 0; i < VX_SIZE; i++)
    // {
    //   // ret = mdRTU_WriteCoil(Slave1_Object, i, wbit[i]);
    //   shellPrint(Shell_Object, "wbit[%d] = 0x%x\r\n", i, wbit[i]);
    // }
#endif
    ret = mdRTU_WriteCoils(Slave1_Object, OUT_DIGITAL_START_ADDR, VX_SIZE, wbit);
    if (ret == mdFALSE)
    {
#if defined(USING_DEBUG)
      shellPrint(Shell_Object, "write failed!\r\n");
#endif
    }
  __exit:
    osDelay(1000);
  }
  /* USER CODE END Control_Task */
}

/* USER CODE BEGIN Header_Transimt_Task */
/**
 * @brief Function implementing the Transimt thread.
 * @param argument: Not used
 * @retval None
 */
#define INCREMENT_COUNT()                                                           \
  do                                                                                \
  {                                                                                 \
    rp_irq->flag = false;                                                           \
    sp_irq->SiteCount = sp_irq->SiteCount ? rp_irq++, (sp_irq->SiteCount - 1U) : 0; \
  } while (0)

#define RESET_POINTER()      \
  do                         \
  {                          \
    rp_irq = sp_irq->pReIRQ; \
  } while (0)
// sp_irq->SiteCount = 0;
// tp_irq = sp_irq->pIRQ;
/* USER CODE END Header_Transimt_Task */
void Transimt_Task(void const *argument)
{
  /* USER CODE BEGIN Transimt_Task */
  // static uint16_t interrupt_record = 0xFFFF, first_interrupt;
  // static Slave_IRQTableTypeDef *sp_irq = &IRQ_Table;
  // static IRQ_Code *tp_irq = NULL;
  // tp_irq = sp_irq->pIRQ;
  // static IRQ_Request *rp_irq = NULL;
  // rp_irq = sp_irq->pReIRQ;
  uint16_t interrupt_record = 0xFFFF, first_interrupt;
  Slave_IRQTableTypeDef *sp_irq = (Slave_IRQTableTypeDef *)argument;
  Save_HandleTypeDef *ps = &Save_Flash;
  IRQ_Code *tp_irq = sp_irq->pIRQ;
  IRQ_Request *rp_irq = sp_irq->pReIRQ;
  uint8_t slave_id = 0x00;
  mdSTATUS ret = mdFALSE;
  // static mdBit wbit[] = {false, false, false, false, false};
  mdBit wbit[VX_SIZE], copy_wbit[VX_SIZE];
  uint8_t target_type[TARGET_BOARD_NUM];
  R_TargetTypeDef record_type = {
      .count = 0,
      .p_id = target_type,
  };
  /* Infinite loop */
  for (;;)
  {
    /*Interrupt request count is not empty*/
    if (xQueueReceive(SureQueueHandle, rp_irq, 0) == pdPASS)
    // if ((sp_irq->SiteCount) && (rp_irq < sp_irq->pReIRQ + sp_irq->SiteCount))
    {
      /*Suspend interrupt processing task*/
      // osThreadSuspend(InterruptHandle);
      // sp_irq->SiteCount = sp_irq->SiteCount ? (sp_irq->SiteCount - 1U) : 0;
      /*Check if the interrupt source is valid*/
      // if ((rp_irq->site) && (rp_irq->flag))
      if (rp_irq && rp_irq->site)
      {
        /*Get the slave ID according to the interrupt number*/
        // slave_id = rp_irq->site - 1U;
        slave_id = (uint8_t)(log(rp_irq->site) / log(2.0));
        /*Set data transmission target channel*/
        MASTER_OBJECT->uartId = 0x01;
        /*Detect whether it is interrupted for the first time*/
        first_interrupt = interrupt_record & rp_irq->site;
        /*Check the first access backplane sign*/
        if (first_interrupt)
        {
          /*Read card type*/
          mdRTU_Master_Codex(MASTER_OBJECT, MODBUS_CODE_17, slave_id, NULL, 0);
        }
        /*The board is not connected to the backplane for the first time*/
        else
        { /*Interrupt device table is not empty*/
          if (sp_irq->TableCount)
          { /*Look for known slaves in the interrupt table*/
            tp_irq = Find_TargetSlave_AdoptId(sp_irq, slave_id);

            /*如果是sp_irq->SiteCount >1,则需要按优先级排序（�???????????????????????个周期仅排序�???????????????????????次），否则直接根据板卡类型处�???????????????????????*/
            /*Interrupt priority sorting is performed when the board is read back*/
            // switch (sp_irq->pIRQ->TypeCoding)
            switch (tp_irq->TypeCoding)
            {
            case Card_AnalogInput:
            {
              mdRTU_Master_Codex(MASTER_OBJECT, MODBUS_CODE_4, tp_irq->SlaveId, NULL, 0);
            }
            break;
            case Card_DigitalInput:
            {
              mdRTU_Master_Codex(MASTER_OBJECT, MODBUS_CODE_2, tp_irq->SlaveId, NULL, 0);
            }
            break;
            /*Invalid board, remove interrupt record table*/
            default:
            {
              /*Read card type*/
              // MASTER_OBJECT->mdRTU_MasterCodex(MASTER_OBJECT, MODBUS_CODE_17, slave_id, NULL, 0);
              mdRTU_Master_Codex(MASTER_OBJECT, MODBUS_CODE_17, slave_id, NULL, 0);
              // INCREMENT_COUNT();
            }
            break;
            }
          }
        }
        /*Clear the flag after the slave responds correctly*/
        if (xTaskNotify(MasterHandle, slave_id, eSetValueWithoutOverwrite) == pdPASS)
        // if (xQueueSend(SureQueueHandle, &slave_id, 10) == pdPASS)
        {
          if (first_interrupt)
          {
            /*Clear first access flag*/
            interrupt_record &= ~rp_irq->site;
          }
          /*Process the next interrupt in the interrupt table*/
          // INCREMENT_COUNT();
        }
        /*no response from slave*/
        else
        {
          if (ps->Param.Slave_IRQ_Table.IRQ_Table_SetFlag == SAVE_SURE_CODE)
          {
#define CARD_ERROR_CODE 23U
            /*Record error code*/
            ps->Param.Error_Code = CARD_ERROR_CODE;
          }
          // INCREMENT_COUNT();
          /*Read card type*/
          // MASTER_OBJECT->mdRTU_MasterCodex(MASTER_OBJECT, MODBUS_CODE_17, slave_id);
          // INCREMENT_COUNT();
#if defined(USING_DEBUG)
          // shellPrint(Shell_Object, "Error: Interrupt Slave 0x%02x No Answer!"__INFORMATION(),
          //            slave_id);
          shellPrint(Shell_Object, "Error: Interrupt Slave 0x%02x No Answer!\r\n",
                     slave_id);
#endif
        }
        /*Task notification delay leads to decrease in recognition success rate*/
        osDelay(20);
      }
      else
      {
        /*Slave error handling*/
#if defined(USING_DEBUG)
        // shellPrint(Shell_Object, "Error: Invalid interrupt source: 0x%x."__INFORMATION(),
        //            sp_irq->pReIRQ[sp_irq->SiteCount].site);
        shellPrint(Shell_Object, "Error: Invalid interrupt source: 0x%x, table_site :0x%p\r\n.",
                   rp_irq->site, rp_irq);
#endif
        // RESET_POINTER();
        // INCREMENT_COUNT();
        // rp_irq->flag = true;
      }
      /*Resume interrupt processing task*/
      // osThreadResume(InterruptHandle);
      // osDelay(100);
    }
    /*One cycle processing completed*/
    else
    {
      // RESET_POINTER();

      ret = mdRTU_ReadCoils(Slave1_Object, OUT_DIGITAL_START_ADDR, VX_SIZE, wbit);
      if (ret == mdFALSE)
      {
#if defined(USING_DEBUG)
        shellPrint(Shell_Object, "read failed!\r\n");
#endif
      }
      else
      {
        if (Check_Vx_State(wbit, copy_wbit, VX_SIZE) && sp_irq->TableCount && record_type.p_id)
        // if (sp_irq->TableCount && record_type.p_id)
        {
          record_type.count = 0;
          if (Save_TargetSlave_Id(sp_irq, Card_DigitalOutput, &record_type))
          {
            /*Set data transmission target channel*/
            MASTER_OBJECT->uartId = 0x01;
            for (uint8_t num = 0; num < TARGET_BOARD_NUM; num++)
            {
              /*Integrated signal source*/
              uint8_t target_value = 0;
              for (uint8_t bit = 0; bit < CARD_SIGNAL_MAX; bit++)
              {
                target_value |= (uint8_t)wbit[bit + num * CARD_SIGNAL_MAX] << bit;
                // target_value = 0xFF;
              }
              if (num < record_type.count)
              {
                mdRTU_Master_Codex(MASTER_OBJECT, MODBUS_CODE_15, record_type.p_id[num], &target_value, 0);
                // // if (xTaskNotify(MasterHandle, record_type.p_id[num], eSetValueWithoutOverwrite) == pdPASS)
                // if (xTaskNotify(MasterHandle, record_type.p_id[num], eSetValueWithOverwrite) == pdPASS)
                // {
                // osDelay(10);
                // }
                xTaskNotify(MasterHandle, record_type.p_id[num], eSetValueWithOverwrite);
                osDelay(50);
                // xQueueSend(SureQueueHandle, &slave_id, 10);
              }
              else
                break;
            }
            // osDelay(200);
          }
        }
      }
    }
    // /*Resume interrupt processing task*/
    // osThreadResume(InterruptHandle);

    osDelay(10);
  }
  /* USER CODE END Transimt_Task */
}

/* USER CODE BEGIN Header_Report_Task */
/**
 * @brief Function implementing the Treport thread.
 * @param argument: Not used
 * @retval None
 */
#define Get_Board_Icon(__type)                                 \
  ((__type) == Card_None ? 0x00 : (__type) >= Card_Wifi ? 0x05 \
                                                        : ((__type) / 0x10 + 1U))
/* USER CODE END Header_Report_Task */
void Report_Task(void const *argument)
{
  /* USER CODE BEGIN Report_Task */

  mdSTATUS ret = mdFALSE;
  mdU16 crbit = mdLow, cwbit = mdLow;
  mdU16 at_state = mdLow;
  mdBit bit = mdLow;
  uint16_t value = 0x0000;
  static bool first_flag = false;
  Save_HandleTypeDef *ps = (Save_HandleTypeDef *)argument;
  Save_User urinfo;
  // osEvent user_event = {
  //     .status = osOK,
  //     .value.p = &urinfo,
  // };
  /* Infinite loop */
  for (;;)
  {
    /*Clear last status*/
    crbit = cwbit = 0;
    for (uint16_t i = 0; i < VX_SIZE; i++)
    {
      ret = mdRTU_ReadInputCoil(Slave1_Object, INPUT_DIGITAL_START_ADDR + i, bit);
      crbit |= i > (CARD_SIGNAL_MAX - 1U) ? (mdU8)(bit << (i - CARD_SIGNAL_MAX)) : (mdU16)(bit << ((i % CARD_SIGNAL_MAX) + CARD_SIGNAL_MAX));
      ret = mdRTU_ReadCoil(Slave1_Object, OUT_DIGITAL_START_ADDR + i, bit);
      cwbit |= i > (CARD_SIGNAL_MAX - 1U) ? (mdU8)(bit << (i - CARD_SIGNAL_MAX)) : (mdU16)(bit << ((i % CARD_SIGNAL_MAX) + CARD_SIGNAL_MAX));
      if (ret == mdFALSE)
      {
#if defined(USING_DEBUG)
        shellPrint(Shell_Object, "Error: Modbus register read failed!" __INFORMATION());
#endif
      }
    }
#if defined(USING_DEBUG)
    // shellPrint(Shell_Object, "rbit = 0x%02x.\r\n", rbit);
#endif
    /*Start signal*/
    Dwin_Object->Dw_Write(Dwin_Object, SS_SIGNAL_ADDR, (uint8_t *)&crbit, sizeof(crbit));
    osDelay(DELAY_TIMES);
    /*User valve*/
    Dwin_Object->Dw_Write(Dwin_Object, USER_TAP_ADDR, (uint8_t *)&cwbit, sizeof(cwbit));
    osDelay(DELAY_TIMES);
    /*Report the status of at module*/
    at_state = Read_ATx_State() << 8U;
    Dwin_Object->Dw_Write(Dwin_Object, ATX_STATE_ADDR, (uint8_t *)&at_state, sizeof(at_state));
    osDelay(DELAY_TIMES);
    if (xQueueReceive(UserQueueHandle, &urinfo, 0) != pdPASS)
    // user_event = osMailGet(UserQueueHandle, osWaitForever);
    // if (user_event.status == osOK)
    {
#if defined(USING_DEBUG)
      shellPrint(Shell_Object, "Error: Failed to receive user parameters!\r\n");
#endif
    }
    else
    {
      for (float *puser = &urinfo.Ptank_M; puser < &urinfo.Ptank_M + BX_SIZE; puser++)
      {
#if defined(USING_DEBUG)
        // shellPrint(Shell_Object, "Value[%d] = %.3fMpa/M3\r\n", i, temp_data[i]);
#endif
        Endian_Swap((uint8_t *)puser, 0U, sizeof(float));
      }
      Dwin_Object->Dw_Write(Dwin_Object, PRESSURE_OUT_ADDR, (uint8_t *)&urinfo, BX_SIZE * sizeof(float));
      osDelay(DELAY_TIMES);
    }
    /*Report error code*/
    if (ps->Param.Error_Code && (ps->Param.Slave_IRQ_Table.IRQ_Table_SetFlag == SAVE_SURE_CODE))
    {
      value = (uint16_t)ps->Param.Error_Code;
      value = (value >> 8U) | (value << 8U);
      Dwin_Object->Dw_Write(Dwin_Object, ERROR_CODE_ADDR, (uint8_t *)&value, sizeof(value));
      value = 0x0100;
      osDelay(DELAY_TIMES);
      Dwin_Object->Dw_Page(Dwin_Object, ERROR_PAGE);
      osDelay(DELAY_TIMES);
      /*Open error animation*/
      Dwin_Object->Dw_Write(Dwin_Object, ERROR_ANMATION, (uint8_t *)&value, sizeof(value));
      first_flag = false;
    }
    else
    {
      if ((!first_flag) && (ps->Param.Slave_IRQ_Table.IRQ_Table_SetFlag == SAVE_SURE_CODE))
      {
        first_flag = true;
        Dwin_Object->Dw_Page(Dwin_Object, MAIN_PAGE);
      }
    }
#if defined(USING_FREERTOS)
    // __exit:
    // CUSTOM_FREE(pdata);
#endif
    osDelay(1000);
  }
  /* USER CODE END Report_Task */
}

/* Report_Callback function */
void Report_Callback(void const *argument)
{
  /* USER CODE BEGIN Report_Callback */
  /*Special attention should be paid here:
  the parameter transfer in the timer is only the timer identifier
  and cannot be used for other parameter pointer transfer*/
#if defined(USING_DEBUG)
  // shellPrint(Shell_Object, "Report_Callback !\r\n");
#endif
  static bool first_flag = false;
  Slave_IRQTableTypeDef *p_irq = &IRQ_Table;
  Save_HandleTypeDef *ps = &Save_Flash;

  if (p_irq && p_irq->TableCount && (!first_flag))
  {
#define BOARD_REPORT_SIZE (sizeof(uint16_t) * CARD_NUM_MAX)
#if defined(USING_FREERTOS)
    uint16_t *pBoard = (uint16_t *)CUSTOM_MALLOC(BOARD_REPORT_SIZE);
    if (pBoard)
    {
#endif
      memset(pBoard, 0x00, BOARD_REPORT_SIZE);
      for (IRQ_Code *p = p_irq->pIRQ; p < p_irq->pIRQ + p_irq->TableCount; p++)
      {
        if (p->SlaveId < BOARD_REPORT_SIZE)
        {
          pBoard[p->SlaveId] = (uint16_t)Get_Board_Icon((uint8_t)p->TypeCoding) << 8U;
#if defined(USING_DEBUG)
          // shellPrint(Shell_Object, "pBoard[%d] = %d\r\n", p->SlaveId, pBoard[p->SlaveId]);
#endif
        }
      }
      /*Report board type*/
      Dwin_Object->Dw_Write(Dwin_Object, BOARD_TYPE_ADDR, (uint8_t *)pBoard, BOARD_REPORT_SIZE);
#if defined(USING_FREERTOS)
    }
    CUSTOM_FREE(pBoard);
#endif
  }
  /*When not configured, update the board information at any time, otherwise it will
  only be updated for the first time*/
  first_flag = (ps->Param.Slave_IRQ_Table.IRQ_Table_SetFlag == SAVE_SURE_CODE) ? true : false;
  /* USER CODE END Report_Callback */
}

/* Modbus_Callback function */
void Modbus_Callback(void const *argument)
{
  /* USER CODE BEGIN Modbus_Callback */
  HAL_GPIO_TogglePin(GPIOB, LED_Pin);
#if defined(USING_DEBUG)
  // shellPrint(Shell_Object, "Modbus_Callback !\r\n");
#endif
  /* USER CODE END Modbus_Callback */
}

/* USER CODE BEGIN Application */
/**
 * @brief  EXTI line detection callback.
 * @param  GPIO_Pin: Specifies the port pin connected to corresponding EXTI line.
 * @retval None
 */
void HAL_GPIO_EXTI_Callback(uint16_t GPIO_Pin)
{
  /* Prevent unused argument(s) compilation warning */
  // UNUSED(GPIO_Pin);
  uint16_t irq_id = GPIO_Pin;
  BaseType_t xHigherPriorityTaskWoken = pdFALSE;
  /*There are other interrupt sources*/
  uint16_t irq_flag = __HAL_GPIO_EXTI_GET_IT(GPIO_PIN_All);
  if (irq_flag)
  {
    irq_id |= irq_flag;
    /*Clear all interrupt signals*/
    __HAL_GPIO_EXTI_CLEAR_IT(GPIO_PIN_All);
  }
  /*Ensure that the message queue has been initialized when the interrupt arrives*/
  if (CodeQueueHandle)
  {
    xQueueSendToBackFromISR(CodeQueueHandle, &irq_id, &xHigherPriorityTaskWoken);
    // xQueueSendFromISR(CodeQueueHandle, &GPIO_Pin, &xHigherPriorityTaskWoken);
    /* Now the buffer is empty we can switch context if necessary. */
    if (xHigherPriorityTaskWoken)
    {
      UBaseType_t uxSavedInterruptStatus = taskENTER_CRITICAL_FROM_ISR();
      /* Actual macro used here is port specific. */
      osThreadYield();
      taskEXIT_CRITICAL_FROM_ISR(uxSavedInterruptStatus);
    }
  }
  /* NOTE: This function Should not be modified, when the callback is needed,
           the HAL_GPIO_EXTI_Callback could be implemented in the user file
   */
}

/* USER CODE END Application */
